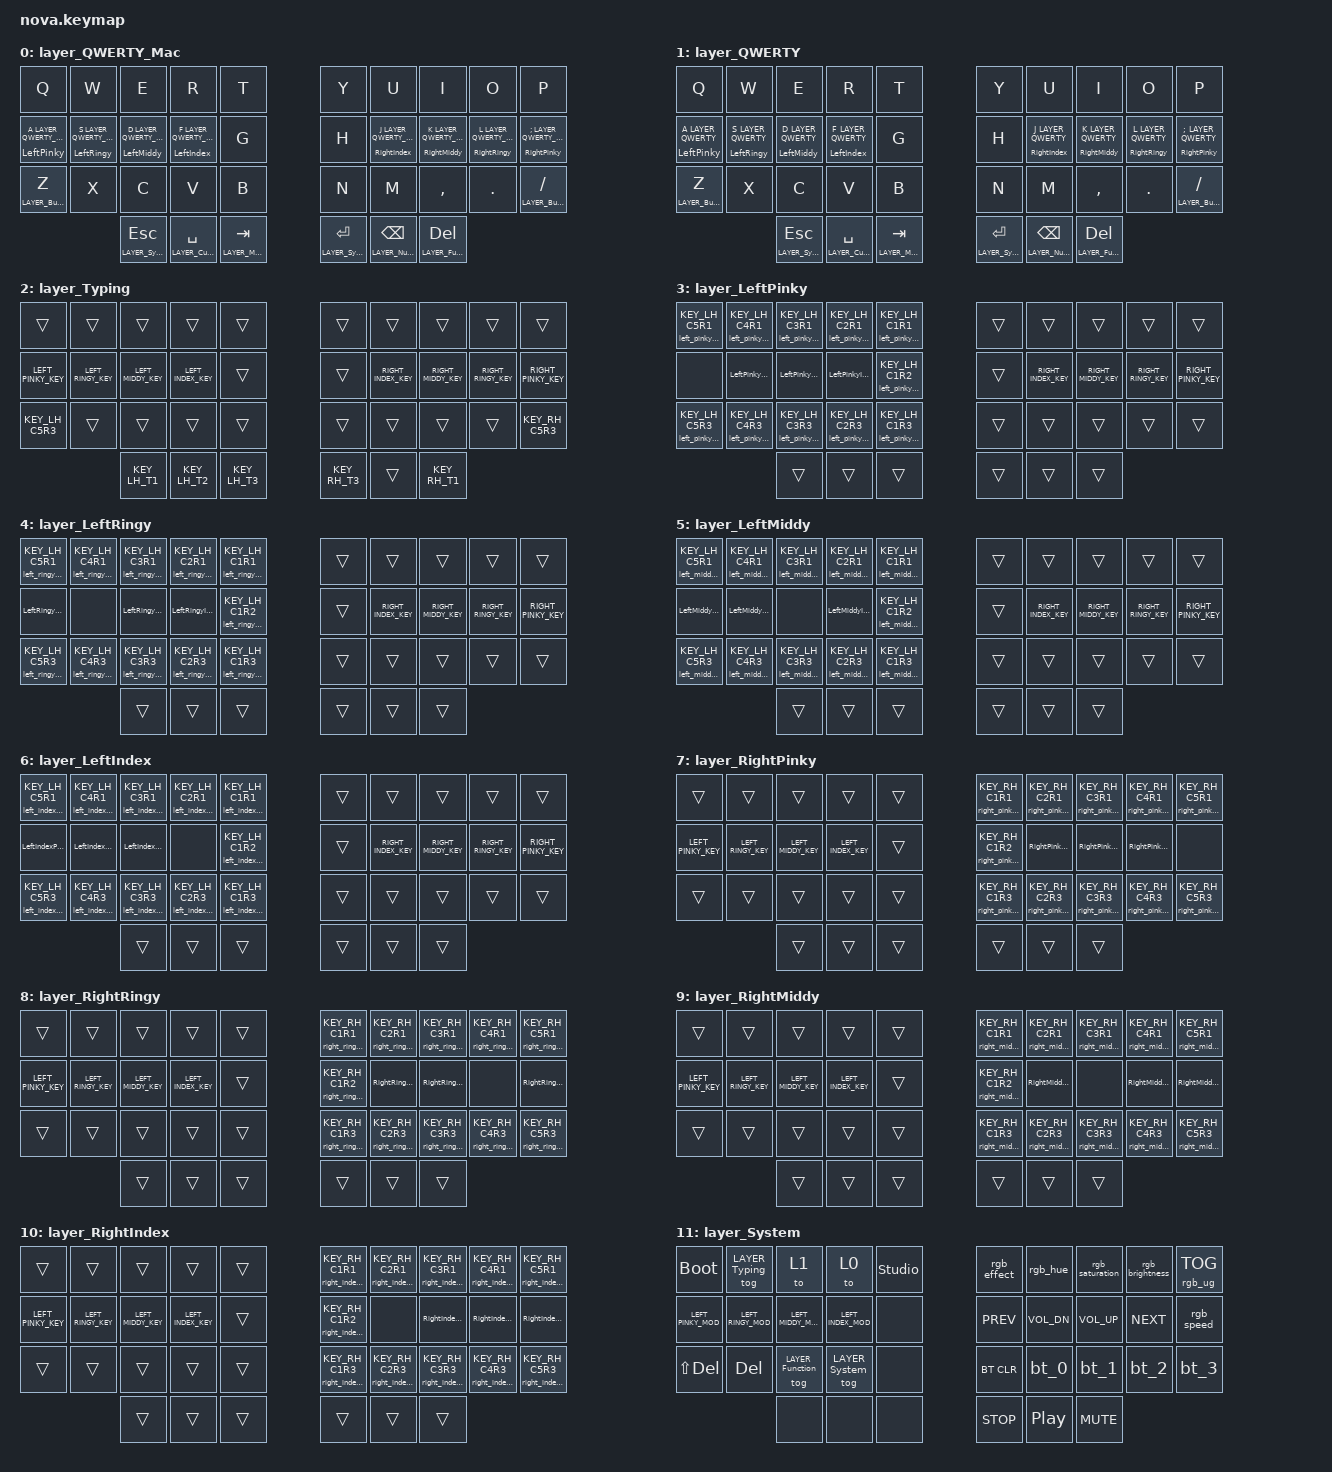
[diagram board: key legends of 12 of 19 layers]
/*
 * Copyright (c) 2020 The ZMK Contributors
 * Copyright (c) 2023 Innaworks Development Limited, trading as MoErgo
 *
 * SPDX-License-Identifier: MIT
 */


/* THIS FILE WAS GENERATED BY GLOVE80 LAYOUT EDITOR
 *
 * This file was generated automatically. You may or may not want to
 * edit it directly.
 */

#include <behaviors.dtsi>
/* Include all behavior includes needed */
#include <dt-bindings/zmk/outputs.h>
#include <dt-bindings/zmk/keys.h>
#include <dt-bindings/zmk/bt.h>
#include <dt-bindings/zmk/rgb.h>

/* On demand includes */


/* Automatically generated layer name #define */
#define LAYER_QWERTY_Mac 0
#define LAYER_QWERTY 1
#define LAYER_Typing 2
#define LAYER_LeftPinky 3
#define LAYER_LeftRingy 4
#define LAYER_LeftMiddy 5
#define LAYER_LeftIndex 6
#define LAYER_RightPinky 7
#define LAYER_RightRingy 8
#define LAYER_RightMiddy 9
#define LAYER_RightIndex 10
#define LAYER_System 11
#define LAYER_Cursor 12
#define LAYER_Mouse 13
#define LAYER_Symbol 14
#define LAYER_Number 15
#define LAYER_Function 16
#define LAYER_Button_Mac 17
#define LAYER_Button 18

#ifndef RGB_STATUS
#define RGB_STATUS 15 0
#endif

/* Custom Device-tree */

/ {
#ifdef BT_DISC_CMD
    behaviors {
        bt_0: bt_0 {
            compatible = "zmk,behavior-tap-dance";
            label = "BT_0";
            #binding-cells = <0>;
            tapping-term-ms = <200>;
            bindings = <&bt_select_0>, <&bt BT_DISC 0>;
        };
        bt_1: bt_1 {
            compatible = "zmk,behavior-tap-dance";
            label = "BT_1";
            #binding-cells = <0>;
            tapping-term-ms = <200>;
            bindings = <&bt_select_1>, <&bt BT_DISC 1>;
        };
        bt_2: bt_2 {
            compatible = "zmk,behavior-tap-dance";
            label = "BT_2";
            #binding-cells = <0>;
            tapping-term-ms = <200>;
            bindings = <&bt_select_2>, <&bt BT_DISC 2>;
        };
        bt_3: bt_3 {
            compatible = "zmk,behavior-tap-dance";
            label = "BT_3";
            #binding-cells = <0>;
            tapping-term-ms = <200>;
            bindings = <&bt_select_3>, <&bt BT_DISC 3>;
        };
    };
    macros {
        bt_select_0: bt_select_0 {
            label = "BT_SELECT_0";
            compatible = "zmk,behavior-macro";
            #binding-cells = <0>;
            bindings
                = <&out OUT_BLE>,
                  <&bt BT_SEL 0>;
        };
        bt_select_1: bt_select_1 {
            label = "BT_SELECT_1";
            compatible = "zmk,behavior-macro";
            #binding-cells = <0>;
            bindings
                = <&out OUT_BLE>,
                  <&bt BT_SEL 1>;
        };
        bt_select_2: bt_select_2 {
            label = "BT_SELECT_2";
            compatible = "zmk,behavior-macro";
            #binding-cells = <0>;
            bindings
                = <&out OUT_BLE>,
                  <&bt BT_SEL 2>;
        };
        bt_select_3: bt_select_3 {
            label = "BT_SELECT_3";
            compatible = "zmk,behavior-macro";
            #binding-cells = <0>;
            bindings
                = <&out OUT_BLE>,
                  <&bt BT_SEL 3>;
        };
    };
#else
    macros {
        bt_0: bt_0 {
            label = "BT_0";
            compatible = "zmk,behavior-macro";
            #binding-cells = <0>;
            bindings
                = <&out OUT_BLE>,
                  <&bt BT_SEL 0>;
        };
        bt_1: bt_1 {
            label = "BT_1";
            compatible = "zmk,behavior-macro";
            #binding-cells = <0>;
            bindings
                = <&out OUT_BLE>,
                  <&bt BT_SEL 1>;
        };
        bt_2: bt_2 {
            label = "BT_2";
            compatible = "zmk,behavior-macro";
            #binding-cells = <0>;
            bindings
                = <&out OUT_BLE>,
                  <&bt BT_SEL 2>;
        };
        bt_3: bt_3 {
            label = "BT_3";
            compatible = "zmk,behavior-macro";
            #binding-cells = <0>;
            bindings
                = <&out OUT_BLE>,
                  <&bt BT_SEL 3>;
        };
    };
#endif
};

/* #define for key positions */
#define POS_LH_T1 30
#define POS_LH_T2 31
#define POS_LH_T3 32
#define POS_LH_C1R1 4
#define POS_LH_C1R2 14
#define POS_LH_C1R3 24
#define POS_LH_C1R4 32
#define POS_LH_C2R1 3
#define POS_LH_C2R2 13
#define POS_LH_C2R3 23
#define POS_LH_C2R4 31
#define POS_LH_C3R1 2
#define POS_LH_C3R2 12
#define POS_LH_C3R3 22
#define POS_LH_C3R4 30
#define POS_LH_C4R1 1
#define POS_LH_C4R2 11
#define POS_LH_C4R3 21
#define POS_LH_C5R1 0
#define POS_LH_C5R2 10
#define POS_LH_C5R3 20
#define POS_RH_T1 35
#define POS_RH_T2 34
#define POS_RH_T3 33
#define POS_RH_C1R1 5
#define POS_RH_C1R2 15
#define POS_RH_C1R3 25
#define POS_RH_C1R4 33
#define POS_RH_C2R1 6
#define POS_RH_C2R2 16
#define POS_RH_C2R3 26
#define POS_RH_C2R4 34
#define POS_RH_C3R1 7
#define POS_RH_C3R2 17
#define POS_RH_C3R3 27
#define POS_RH_C3R4 35
#define POS_RH_C4R1 8
#define POS_RH_C4R2 18
#define POS_RH_C4R3 28
#define POS_RH_C5R1 9
#define POS_RH_C5R2 19
#define POS_RH_C5R3 29

/* Custom Defined Behaviors */
/ {
// NOTE: Use the many #define settings below to customize this keymap!
#define DIFFICULTY_LEVEL  0  // 0:custom, 1:easy -> 5:hard (see below)
#define ENFORCE_BILATERAL    // cancels single-handed home row mod+tap
#define SPACE_FORGIVENESS    // allow lingering taps on the space bar
// TIP: Add more setting overrides here instead of editing them below.

//////////////////////////////////////////////////////////////////////////////
//
// Sunaku's Keymap v41 -- "Glorious Engrammer"
// - https://github.com/sunaku/glove80-keymaps
//
//////////////////////////////////////////////////////////////////////////////

//
// OPERATING_SYSTEM defines which operating system you intend to use
// with this keymap, because shortcuts vary across operating systems.
//
// - https://zmk.dev/docs/codes
// - https://en.wikipedia.org/wiki/Table_of_keyboard_shortcuts
//
// This setting also affects the UNICODE() function defined below, as
// each OS has different shortcuts for typing Unicode hex characters.
//
// NOTE: You may need to enable Unicode hexadecimal input in your OS:
// - (macOS) https://uknowit.uwgb.edu/page.php?id=22623
//     and   https://github.com/ldanet/unicode-hex-input-fix
// - (Linux) https://help.ubuntu.com/stable/ubuntu-help/tips-specialchars.html.en#ctrlshiftu
// - (Windows) https://github.com/samhocevar/wincompose
//
// Specifically, Windows users should be running the WinCompose tool,
// which lets you type Unicode characters via hexadecimal codepoints.
//
// Windows/Linux Def
#define _C      LC
#define _REDO   _C(Y)
#define _UNDO   _C(Z)
#define _CUT    _C(X)
#define _COPY   _C(C)
#define _PASTE  _C(V)
#define _FIND   _C(F)
// Mac Def
#define _C_Mac      LG
#define _REDO_Mac   _C_Mac(LS(Z))
#define _HOME_Mac   _C_Mac(LEFT)
#define _END_Mac    _C_Mac(RIGHT)
#define _UNDO_Mac   _C_Mac(Z)
#define _CUT_Mac    _C_Mac(X)
#define _COPY_Mac   _C_Mac(C)
#define _PASTE_Mac  _C_Mac(V)
#define _FIND_Mac   _C_Mac(F)
#define _PSCRN_Mac  _C_Mac(LS(N4))

//
// Keymap specific knowledge of the base layer's alpha + ZMK layout
//
#define KEY_LH_C5R1 Q
#define KEY_LH_C4R1 W
#define KEY_LH_C3R1 E
#define KEY_LH_C2R1 R
#define KEY_LH_C1R1 T
#define KEY_RH_C1R1 Y
#define KEY_RH_C2R1 U
#define KEY_RH_C3R1 I
#define KEY_RH_C4R1 O
#define KEY_RH_C5R1 P
#define KEY_LH_C5R2 A
#define KEY_LH_C4R2 S
#define KEY_LH_C3R2 D
#define KEY_LH_C2R2 F
#define KEY_LH_C1R2 G
#define KEY_RH_C1R2 H
#define KEY_RH_C2R2 J
#define KEY_RH_C3R2 K
#define KEY_RH_C4R2 L
#define KEY_RH_C5R2 SEMI
#define KEY_LH_C5R3 Z
#define KEY_LH_C4R3 X
#define KEY_LH_C3R3 C
#define KEY_LH_C2R3 V
#define KEY_LH_C1R3 B
#define KEY_RH_C1R3 N
#define KEY_RH_C2R3 M
#define KEY_RH_C3R3 COMMA
#define KEY_RH_C4R3 DOT
#define KEY_RH_C5R3 FSLH
#define KEY_LH_T1 ESC
#define KEY_LH_T2 SPACE
#define KEY_LH_T3 TAB
#define KEY_RH_T3 ENTER
#define KEY_RH_T2 BACKSPACE
#define KEY_RH_T1 DELETE

combos {
  compatible = "zmk,combos";

  //
  // COMBO_FIRING_DECAY defines how much time you have left (milliseconds)
  // after pressing the first key in a ZMK combo to finish the whole chord.
  //
  #ifndef COMBO_FIRING_DECAY
  #define COMBO_FIRING_DECAY 50
  #endif
  combo_caps_lock {
    timeout-ms = <COMBO_FIRING_DECAY>;
    key-positions = <POS_LH_T3 POS_RH_T3>;
    bindings = <&kp CAPSLOCK>;
    layers = <0 1 2 3 4 5 6 7>;
  };
};

behaviors {

  //////////////////////////////////////////////////////////////////////////
  //
  // Miryoku layers and home row mods (ported from my QMK endgame)
  // - https://sunaku.github.io/home-row-mods.html#porting-to-zmk
  // - https://github.com/urob/zmk-config#timeless-homerow-mods
  //
  //////////////////////////////////////////////////////////////////////////

  //
  // DIFFICULTY_LEVEL specifies your level of expertise with this keymap.
  // It's meant to help newcomers gradually work their way up to mastery.
  //
  // #define DIFFICULTY_LEVEL 1 // novice (500ms)
  // #define DIFFICULTY_LEVEL 2 // slower (400ms)
  // #define DIFFICULTY_LEVEL 3 // normal (300ms)
  // #define DIFFICULTY_LEVEL 4 // faster (200ms)
  // #define DIFFICULTY_LEVEL 5 // expert (100ms)
  //
  // You can disable this setting by omitting it or assigning a `0` zero,
  // in which case it will default to my personal set of time thresholds.
  //
  // #define DIFFICULTY_LEVEL 0 // sunaku (150ms)
  //
  // No matter what difficulty level you choose, you can always override
  // any settings in this keymap at the beginning of this configuration.
  //
  #ifdef DIFFICULTY_LEVEL
    #if DIFFICULTY_LEVEL > 0 && DIFFICULTY_LEVEL < 6
      #ifndef TAPPING_RESOLUTION
        #define TAPPING_RESOLUTION ((6 - DIFFICULTY_LEVEL) * 100)
      #endif
    #endif
  #endif

  //
  // TAPPING_RESOLUTION specifies the maximum speed at which the keyboard
  // confuses your taps as being holds when you type on home row mod keys.
  // When you lower this value, the same confusion should still occur; but
  // when you raise this value, you should be able to type normally again.
  //
  #ifndef TAPPING_RESOLUTION
  #define TAPPING_RESOLUTION 150
  #endif

  //
  // ENFORCE_BILATERAL cancels out single-handed home row mods activation by
  // releasing any currently pressed mods and replacing them with plain taps.
  //
  // NOTE: You may still encounter "flashing mods" where an operating system
  // action is triggered by the release of mods, such as LGUI which launches
  // the Windows Start Menu and LALT which opens the Microsoft Office Ribbon.
  //
  //#define ENFORCE_BILATERAL

  //
  // SPACE_FORGIVENESS taps when the symbol layer access key is merely held
  // and released, without any symbol been tapped while the access was held.
  // For example, suppose you hold the symbol layer key and, before pressing
  // another key, you suddenly decide that you don't want the layer anymore:
  //
  // <1> If this setting is enabled, the underlying tap behavior is triggered
  //     to type a single character when you release that layer access key.
  //
  // <2> Otherwise, nothing happens when you release that layer access key.
  //
  // NOTE: This setting interferes with (and effectively disables) per-key
  // RGB indicators (PR30) for layers accessed via thumb layer access keys.
  //
  //#define SPACE_FORGIVENESS

  //
  // The *_FINGER_MOD specify which modifiers are used by home row mod keys.
  // Here, we use Miryoku's "GACS" (Win, Alt, Ctrl, Shift) order by default.
  //
  #ifndef PINKY_FINGER_MOD
  #define PINKY_FINGER_MOD LGUI
  #endif
  #ifndef RINGY_FINGER_MOD
  #define RINGY_FINGER_MOD LALT
  #endif
  #ifndef MIDDY_FINGER_MOD
  #define MIDDY_FINGER_MOD LCTL
  #endif
  #ifndef INDEX_FINGER_MOD
  #define INDEX_FINGER_MOD LSFT
  #endif
  //
  // The following settings let you configure mods individually, per finger:
  //
  #ifndef LEFT_PINKY_MOD
  #define LEFT_PINKY_MOD PINKY_FINGER_MOD
  #endif
  #ifndef RIGHT_PINKY_MOD
  #define RIGHT_PINKY_MOD PINKY_FINGER_MOD
  #endif
  #ifndef LEFT_RINGY_MOD
  #define LEFT_RINGY_MOD RINGY_FINGER_MOD
  #endif
  #ifndef RIGHT_RINGY_MOD
  #define RIGHT_RINGY_MOD RINGY_FINGER_MOD
  #endif
  #ifndef LEFT_MIDDY_MOD
  #define LEFT_MIDDY_MOD MIDDY_FINGER_MOD
  #endif
  #ifndef RIGHT_MIDDY_MOD
  #define RIGHT_MIDDY_MOD MIDDY_FINGER_MOD
  #endif
  #ifndef LEFT_INDEX_MOD
  #define LEFT_INDEX_MOD INDEX_FINGER_MOD
  #endif
  #ifndef RIGHT_INDEX_MOD
  #define RIGHT_INDEX_MOD INDEX_FINGER_MOD
  #endif

  //
  // HOMEY_HOLDING_TYPE defines the flavor of ZMK hold-tap behavior to use
  // for the pinky, ring, and middle fingers (which are assigned to Super,
  // Alt, and Ctrl respectively in the Miryoku system) on home row keys.
  //
  #ifndef HOMEY_HOLDING_TYPE
  #define HOMEY_HOLDING_TYPE "tap-preferred"
  #endif

  //
  // HOMEY_HOLDING_TIME defines how long you need to hold (milliseconds)
  // home row mod keys in order to send their modifiers to the computer
  // (i.e. "register" them) for mod-click mouse usage (e.g. Ctrl-Click).
  //
  #ifndef HOMEY_HOLDING_TIME
  #define HOMEY_HOLDING_TIME (TAPPING_RESOLUTION + 90)
  #endif
  #ifndef INDEX_HOLDING_TIME
  #define INDEX_HOLDING_TIME (TAPPING_RESOLUTION + 20)
  #endif
  #ifndef MIDDY_HOLDING_TIME
  #define MIDDY_HOLDING_TIME (TAPPING_RESOLUTION + 60)
  #endif
  #ifndef RINGY_HOLDING_TIME
  #define RINGY_HOLDING_TIME (TAPPING_RESOLUTION + 90)
  #endif
  #ifndef PINKY_HOLDING_TIME
  #define PINKY_HOLDING_TIME (TAPPING_RESOLUTION + 110)
  #endif

  //
  // HOMEY_STREAK_DECAY defines how long you need to wait (milliseconds)
  // after typing before you can use home row mods again.  It prevents
  // unintended activation of home row mods when you're actively typing.
  //
  #ifndef HOMEY_STREAK_DECAY
  #define HOMEY_STREAK_DECAY TAPPING_RESOLUTION
  #endif

  //
  // HOMEY_REPEAT_DECAY defines how much time you have left (milliseconds)
  // after tapping a key to hold it again in order to make it auto-repeat.
  //
  #ifndef HOMEY_REPEAT_DECAY
  #define HOMEY_REPEAT_DECAY (TAPPING_RESOLUTION + 150)
  #endif // "tap then hold" for key auto-repeat

  //
  // CHORD_HOLDING_TYPE defines the flavor of ZMK hold-tap behavior to use
  // for chorded home row mods (secondary keypresses in multi-mod chords).
  //
  #ifndef CHORD_HOLDING_TYPE
  #define CHORD_HOLDING_TYPE HOMEY_HOLDING_TYPE
  #endif

  //
  // CHORD_HOLDING_TIME defines how long you need to hold (milliseconds)
  // home row mod keys in order to send their modifiers to the computer
  // (i.e. "register" them) for mod-click mouse usage (e.g. Ctrl-Click).
  // This is specifically for secondary keypresses in multi-mod chords.
  //
  #ifndef CHORD_HOLDING_TIME
  #define CHORD_HOLDING_TIME TAPPING_RESOLUTION
  #endif

  //
  // CHORD_STREAK_DECAY defines how long you need to wait (milliseconds)
  // after typing before you can use home row mods again.  It prevents
  // unintended activation of home row mods when you're actively typing
  // This is specifically for secondary keypresses in multi-mod chords.
  //
  #ifndef CHORD_STREAK_DECAY
  #define CHORD_STREAK_DECAY HOMEY_STREAK_DECAY
  #endif

  //
  // CHORD_REPEAT_DECAY defines how much time you have left (milliseconds)
  // after tapping a key to hold it again in order to make it auto-repeat.
  // This is specifically for secondary keypresses in multi-mod chords.
  //
  #ifndef CHORD_REPEAT_DECAY
  #define CHORD_REPEAT_DECAY HOMEY_REPEAT_DECAY
  #endif

  //
  // INDEX_HOLDING_TYPE defines the flavor of ZMK hold-tap behavior to use
  // for index fingers (which Miryoku assigns to Shift) on home row keys.
  //
  // NOTE: The "tap-preferred" flavor of ZMK hold-tap for index finger keys
  // allows faster activation of the Shift modifier (without having to wait
  // for the modified key to be released as the "balanced" flavor requires).
  //
  #ifndef INDEX_HOLDING_TYPE
  #define INDEX_HOLDING_TYPE "tap-preferred"
  #endif

  //
  // INDEX_STREAK_DECAY defines how long you need to wait (milliseconds)
  // after typing before you can use home row mods again.  It prevents
  // unintended activation of home row mods when you're actively typing.
  //
  #ifndef INDEX_STREAK_DECAY
  #define INDEX_STREAK_DECAY (TAPPING_RESOLUTION - 50)
  #endif

  //
  // INDEX_REPEAT_DECAY defines how much time you have left (milliseconds)
  // after tapping a key to hold it again in order to make it auto-repeat.
  //
  #ifndef INDEX_REPEAT_DECAY
  #define INDEX_REPEAT_DECAY (TAPPING_RESOLUTION + 150)
  #endif // "tap then hold" for key auto-repeat

  //
  // PLAIN_HOLDING_TYPE defines the flavor of ZMK hold-tap behavior to use
  // for index fingers (which Miryoku assigns to Shift) on home row keys.
  //
  // NOTE: The "tap-preferred" flavor of ZMK hold-tap for index finger keys
  // allows faster activation of the Shift modifier (without having to wait
  // for the modified key to be released as the "balanced" flavor requires).
  //
  #ifndef PLAIN_HOLDING_TYPE
  #define PLAIN_HOLDING_TYPE INDEX_HOLDING_TYPE
  #endif

  //
  // PLAIN_HOLDING_TIME defines how long you need to hold (milliseconds)
  // index finger keys in order to send their modifiers to the computer
  // (i.e. "register" them) for mod-click mouse usage (e.g. Shift-Click).
  //
  #ifndef PLAIN_HOLDING_TIME
  #define PLAIN_HOLDING_TIME (TAPPING_RESOLUTION + 50)
  #endif

  //
  // PLAIN_STREAK_DECAY defines how long you need to wait (milliseconds)
  // after typing before you can use home row mods again.  It prevents
  // unintended activation of home row mods when you're actively typing.
  //
  #ifndef PLAIN_STREAK_DECAY
  #define PLAIN_STREAK_DECAY HOMEY_STREAK_DECAY
  #endif

  //
  // PLAIN_REPEAT_DECAY defines how much time you have left (milliseconds)
  // after tapping a key to hold it again in order to make it auto-repeat.
  //
  #ifndef PLAIN_REPEAT_DECAY
  #define PLAIN_REPEAT_DECAY (TAPPING_RESOLUTION + 150)
  #endif // "tap then hold" for key auto-repeat

  //
  // THUMB_HOLDING_TYPE defines the flavor of ZMK hold-tap behavior to use
  // for the thumbs (which are assigned to 6 layers in the Miryoku system).
  //
  // NOTE: The "balanced" flavor of ZMK hold-tap provides instant modifier
  // activation for the symbol layer (if the tapped symbol key is released
  // while the thumb layer key is still held down) for quicker programming.
  //
  #ifndef THUMB_HOLDING_TYPE
  #define THUMB_HOLDING_TYPE "balanced"
  #endif

  //
  // THUMB_HOLDING_TIME defines how long you need to hold (milliseconds)
  // a thumb key to activate a layer.  Shorter holds are treated as taps.
  //
  #ifndef THUMB_HOLDING_TIME
  #define THUMB_HOLDING_TIME (TAPPING_RESOLUTION + 50)
  #endif

  //
  // THUMB_REPEAT_DECAY defines how much time you have left (milliseconds)
  // after tapping a key to hold it again in order to make it auto-repeat.
  //
  #ifndef THUMB_REPEAT_DECAY
  #define THUMB_REPEAT_DECAY (TAPPING_RESOLUTION + 150)
  #endif // "tap then hold" for key auto-repeat

  //
  // SPACE_HOLDING_TYPE defines the flavor of ZMK hold-tap behavior to use
  // for spacebar (assigned to the right thumb's home position by default).
  //
  #ifndef SPACE_HOLDING_TYPE
  #define SPACE_HOLDING_TYPE THUMB_HOLDING_TYPE
  #endif

  //
  // SPACE_HOLDING_TIME defines how long you need to hold (milliseconds)
  // the space thumb key to activate.  Shorter holds are treated as taps.
  //
  #ifndef SPACE_HOLDING_TIME
  #define SPACE_HOLDING_TIME (TAPPING_RESOLUTION + 20)
  #endif

  //
  // SPACE_REPEAT_DECAY defines how much time you have left (milliseconds)
  // after tapping a key to hold it again in order to make it auto-repeat.
  //
  #ifndef SPACE_REPEAT_DECAY
  #define SPACE_REPEAT_DECAY TAPPING_RESOLUTION
  #endif

  //
  // Nova key positions index for positional hold-tap
  //
  // |--------------------|--------------------|
  // | LEFT_HAND_KEYS     |    RIGHT_HAND_KEYS |
  // |                    |                    |
  // |  0  1  2  3  4     |      5  6  7  8  9 |
  // | 10 11 12 13 14     |     15 16 17 18 19 |
  // | 20 21 22 23 24     |     25 26 27 28 29 |
  // |       30 31 32     |     33 34 35       |
  // |--------------------|--------------------|
  //
  #define LEFT_HAND_KEYS  \
          0  1  2  3  4   \
         10 11 12 13 14   \
         20 21 22 23 24
  #define RIGHT_HAND_KEYS \
                                 5  6  7  8  9 \
                                15 16 17 18 19 \
                                25 26 27 28 29
  #define THUMB_KEYS      \
               30 31 32         33 34 35

  #define LEFT_PINKY_KEY  KEY_LH_C5R2
  #define LEFT_RINGY_KEY  KEY_LH_C4R2
  #define LEFT_MIDDY_KEY  KEY_LH_C3R2
  #define LEFT_INDEX_KEY  KEY_LH_C2R2

  #define RIGHT_PINKY_KEY KEY_RH_C5R2
  #define RIGHT_RINGY_KEY KEY_RH_C4R2
  #define RIGHT_MIDDY_KEY KEY_RH_C3R2
  #define RIGHT_INDEX_KEY KEY_RH_C2R2

  //
  // Home row mods with bilateral combinations support
  //
  #ifndef PINKY_HOLDING_TYPE
  #define PINKY_HOLDING_TYPE HOMEY_HOLDING_TYPE
  #endif
  #ifndef PINKY_CHORD_HOLDING_TYPE
  #define PINKY_CHORD_HOLDING_TYPE CHORD_HOLDING_TYPE
  #endif
  #ifndef LEFT_PINKY_CHORD_HOLDING_TYPE
  #define LEFT_PINKY_CHORD_HOLDING_TYPE PINKY_CHORD_HOLDING_TYPE
  #endif
  #ifndef RIGHT_PINKY_CHORD_HOLDING_TYPE
  #define RIGHT_PINKY_CHORD_HOLDING_TYPE PINKY_CHORD_HOLDING_TYPE
  #endif
  #ifndef PINKY_HOLDING_TIME
  #define PINKY_HOLDING_TIME HOMEY_HOLDING_TIME
  #endif
  #ifndef PINKY_CHORD_HOLDING_TIME
  #define PINKY_CHORD_HOLDING_TIME CHORD_HOLDING_TIME
  #endif
  #ifndef LEFT_PINKY_CHORD_HOLDING_TIME
  #define LEFT_PINKY_CHORD_HOLDING_TIME PINKY_CHORD_HOLDING_TIME
  #endif
  #ifndef RIGHT_PINKY_CHORD_HOLDING_TIME
  #define RIGHT_PINKY_CHORD_HOLDING_TIME PINKY_CHORD_HOLDING_TIME
  #endif
  #ifndef PINKY_STREAK_DECAY
  #define PINKY_STREAK_DECAY HOMEY_STREAK_DECAY
  #endif
  #ifndef PINKY_CHORD_STREAK_DECAY
  #define PINKY_CHORD_STREAK_DECAY CHORD_STREAK_DECAY
  #endif
  #ifndef LEFT_PINKY_CHORD_STREAK_DECAY
  #define LEFT_PINKY_CHORD_STREAK_DECAY PINKY_CHORD_STREAK_DECAY
  #endif
  #ifndef RIGHT_PINKY_CHORD_STREAK_DECAY
  #define RIGHT_PINKY_CHORD_STREAK_DECAY PINKY_CHORD_STREAK_DECAY
  #endif
  #ifndef PINKY_REPEAT_DECAY
  #define PINKY_REPEAT_DECAY HOMEY_REPEAT_DECAY
  #endif
  #ifndef PINKY_CHORD_REPEAT_DECAY
  #define PINKY_CHORD_REPEAT_DECAY CHORD_REPEAT_DECAY
  #endif
  #ifndef LEFT_PINKY_CHORD_REPEAT_DECAY
  #define LEFT_PINKY_CHORD_REPEAT_DECAY PINKY_CHORD_REPEAT_DECAY
  #endif
  #ifndef RIGHT_PINKY_CHORD_REPEAT_DECAY
  #define RIGHT_PINKY_CHORD_REPEAT_DECAY PINKY_CHORD_REPEAT_DECAY
  #endif
  #ifndef RINGY_HOLDING_TYPE
  #define RINGY_HOLDING_TYPE HOMEY_HOLDING_TYPE
  #endif
  #ifndef RINGY_CHORD_HOLDING_TYPE
  #define RINGY_CHORD_HOLDING_TYPE CHORD_HOLDING_TYPE
  #endif
  #ifndef LEFT_RINGY_CHORD_HOLDING_TYPE
  #define LEFT_RINGY_CHORD_HOLDING_TYPE RINGY_CHORD_HOLDING_TYPE
  #endif
  #ifndef RIGHT_RINGY_CHORD_HOLDING_TYPE
  #define RIGHT_RINGY_CHORD_HOLDING_TYPE RINGY_CHORD_HOLDING_TYPE
  #endif
  #ifndef RINGY_HOLDING_TIME
  #define RINGY_HOLDING_TIME HOMEY_HOLDING_TIME
  #endif
  #ifndef RINGY_CHORD_HOLDING_TIME
  #define RINGY_CHORD_HOLDING_TIME CHORD_HOLDING_TIME
  #endif
  #ifndef LEFT_RINGY_CHORD_HOLDING_TIME
  #define LEFT_RINGY_CHORD_HOLDING_TIME RINGY_CHORD_HOLDING_TIME
  #endif
  #ifndef RIGHT_RINGY_CHORD_HOLDING_TIME
  #define RIGHT_RINGY_CHORD_HOLDING_TIME RINGY_CHORD_HOLDING_TIME
  #endif
  #ifndef RINGY_STREAK_DECAY
  #define RINGY_STREAK_DECAY HOMEY_STREAK_DECAY
  #endif
  #ifndef RINGY_CHORD_STREAK_DECAY
  #define RINGY_CHORD_STREAK_DECAY CHORD_STREAK_DECAY
  #endif
  #ifndef LEFT_RINGY_CHORD_STREAK_DECAY
  #define LEFT_RINGY_CHORD_STREAK_DECAY RINGY_CHORD_STREAK_DECAY
  #endif
  #ifndef RIGHT_RINGY_CHORD_STREAK_DECAY
  #define RIGHT_RINGY_CHORD_STREAK_DECAY RINGY_CHORD_STREAK_DECAY
  #endif
  #ifndef RINGY_REPEAT_DECAY
  #define RINGY_REPEAT_DECAY HOMEY_REPEAT_DECAY
  #endif
  #ifndef RINGY_CHORD_REPEAT_DECAY
  #define RINGY_CHORD_REPEAT_DECAY CHORD_REPEAT_DECAY
  #endif
  #ifndef LEFT_RINGY_CHORD_REPEAT_DECAY
  #define LEFT_RINGY_CHORD_REPEAT_DECAY RINGY_CHORD_REPEAT_DECAY
  #endif
  #ifndef RIGHT_RINGY_CHORD_REPEAT_DECAY
  #define RIGHT_RINGY_CHORD_REPEAT_DECAY RINGY_CHORD_REPEAT_DECAY
  #endif
  #ifndef MIDDY_HOLDING_TYPE
  #define MIDDY_HOLDING_TYPE HOMEY_HOLDING_TYPE
  #endif
  #ifndef MIDDY_CHORD_HOLDING_TYPE
  #define MIDDY_CHORD_HOLDING_TYPE CHORD_HOLDING_TYPE
  #endif
  #ifndef LEFT_MIDDY_CHORD_HOLDING_TYPE
  #define LEFT_MIDDY_CHORD_HOLDING_TYPE MIDDY_CHORD_HOLDING_TYPE
  #endif
  #ifndef RIGHT_MIDDY_CHORD_HOLDING_TYPE
  #define RIGHT_MIDDY_CHORD_HOLDING_TYPE MIDDY_CHORD_HOLDING_TYPE
  #endif
  #ifndef MIDDY_HOLDING_TIME
  #define MIDDY_HOLDING_TIME HOMEY_HOLDING_TIME
  #endif
  #ifndef MIDDY_CHORD_HOLDING_TIME
  #define MIDDY_CHORD_HOLDING_TIME CHORD_HOLDING_TIME
  #endif
  #ifndef LEFT_MIDDY_CHORD_HOLDING_TIME
  #define LEFT_MIDDY_CHORD_HOLDING_TIME MIDDY_CHORD_HOLDING_TIME
  #endif
  #ifndef RIGHT_MIDDY_CHORD_HOLDING_TIME
  #define RIGHT_MIDDY_CHORD_HOLDING_TIME MIDDY_CHORD_HOLDING_TIME
  #endif
  #ifndef MIDDY_STREAK_DECAY
  #define MIDDY_STREAK_DECAY HOMEY_STREAK_DECAY
  #endif
  #ifndef MIDDY_CHORD_STREAK_DECAY
  #define MIDDY_CHORD_STREAK_DECAY CHORD_STREAK_DECAY
  #endif
  #ifndef LEFT_MIDDY_CHORD_STREAK_DECAY
  #define LEFT_MIDDY_CHORD_STREAK_DECAY MIDDY_CHORD_STREAK_DECAY
  #endif
  #ifndef RIGHT_MIDDY_CHORD_STREAK_DECAY
  #define RIGHT_MIDDY_CHORD_STREAK_DECAY MIDDY_CHORD_STREAK_DECAY
  #endif
  #ifndef MIDDY_REPEAT_DECAY
  #define MIDDY_REPEAT_DECAY HOMEY_REPEAT_DECAY
  #endif
  #ifndef MIDDY_CHORD_REPEAT_DECAY
  #define MIDDY_CHORD_REPEAT_DECAY CHORD_REPEAT_DECAY
  #endif
  #ifndef LEFT_MIDDY_CHORD_REPEAT_DECAY
  #define LEFT_MIDDY_CHORD_REPEAT_DECAY MIDDY_CHORD_REPEAT_DECAY
  #endif
  #ifndef RIGHT_MIDDY_CHORD_REPEAT_DECAY
  #define RIGHT_MIDDY_CHORD_REPEAT_DECAY MIDDY_CHORD_REPEAT_DECAY
  #endif
  #ifndef INDEX_HOLDING_TYPE
  #define INDEX_HOLDING_TYPE HOMEY_HOLDING_TYPE
  #endif
  #ifndef INDEX_CHORD_HOLDING_TYPE
  #define INDEX_CHORD_HOLDING_TYPE CHORD_HOLDING_TYPE
  #endif
  #ifndef LEFT_INDEX_CHORD_HOLDING_TYPE
  #define LEFT_INDEX_CHORD_HOLDING_TYPE INDEX_CHORD_HOLDING_TYPE
  #endif
  #ifndef RIGHT_INDEX_CHORD_HOLDING_TYPE
  #define RIGHT_INDEX_CHORD_HOLDING_TYPE INDEX_CHORD_HOLDING_TYPE
  #endif
  #ifndef INDEX_HOLDING_TIME
  #define INDEX_HOLDING_TIME HOMEY_HOLDING_TIME
  #endif
  #ifndef INDEX_CHORD_HOLDING_TIME
  #define INDEX_CHORD_HOLDING_TIME CHORD_HOLDING_TIME
  #endif
  #ifndef LEFT_INDEX_CHORD_HOLDING_TIME
  #define LEFT_INDEX_CHORD_HOLDING_TIME INDEX_CHORD_HOLDING_TIME
  #endif
  #ifndef RIGHT_INDEX_CHORD_HOLDING_TIME
  #define RIGHT_INDEX_CHORD_HOLDING_TIME INDEX_CHORD_HOLDING_TIME
  #endif
  #ifndef INDEX_STREAK_DECAY
  #define INDEX_STREAK_DECAY HOMEY_STREAK_DECAY
  #endif
  #ifndef INDEX_CHORD_STREAK_DECAY
  #define INDEX_CHORD_STREAK_DECAY CHORD_STREAK_DECAY
  #endif
  #ifndef LEFT_INDEX_CHORD_STREAK_DECAY
  #define LEFT_INDEX_CHORD_STREAK_DECAY INDEX_CHORD_STREAK_DECAY
  #endif
  #ifndef RIGHT_INDEX_CHORD_STREAK_DECAY
  #define RIGHT_INDEX_CHORD_STREAK_DECAY INDEX_CHORD_STREAK_DECAY
  #endif
  #ifndef INDEX_REPEAT_DECAY
  #define INDEX_REPEAT_DECAY HOMEY_REPEAT_DECAY
  #endif
  #ifndef INDEX_CHORD_REPEAT_DECAY
  #define INDEX_CHORD_REPEAT_DECAY CHORD_REPEAT_DECAY
  #endif
  #ifndef LEFT_INDEX_CHORD_REPEAT_DECAY
  #define LEFT_INDEX_CHORD_REPEAT_DECAY INDEX_CHORD_REPEAT_DECAY
  #endif
  #ifndef RIGHT_INDEX_CHORD_REPEAT_DECAY
  #define RIGHT_INDEX_CHORD_REPEAT_DECAY INDEX_CHORD_REPEAT_DECAY
  #endif
  #ifndef LEFT_PINKY_HOLDING_TYPE
  #define LEFT_PINKY_HOLDING_TYPE PINKY_HOLDING_TYPE
  #endif
  #ifndef LEFT_PINKY_HOLDING_TIME
  #define LEFT_PINKY_HOLDING_TIME PINKY_HOLDING_TIME
  #endif
  #ifndef LEFT_PINKY_STREAK_DECAY
  #define LEFT_PINKY_STREAK_DECAY PINKY_STREAK_DECAY
  #endif
  #ifndef LEFT_PINKY_REPEAT_DECAY
  #define LEFT_PINKY_REPEAT_DECAY PINKY_REPEAT_DECAY
  #endif
  left_pinky: homey_left_pinky {
    compatible = "zmk,behavior-hold-tap";
    flavor = LEFT_PINKY_HOLDING_TYPE;
    hold-trigger-key-positions = <RIGHT_HAND_KEYS THUMB_KEYS>;
    hold-trigger-on-release; // wait for other home row mods
    tapping-term-ms = <LEFT_PINKY_HOLDING_TIME>;
    quick-tap-ms = <LEFT_PINKY_REPEAT_DECAY>;
    require-prior-idle-ms = <LEFT_PINKY_STREAK_DECAY>;
    #binding-cells = <2>;
    bindings = <&kp>, <&kp>;
  };
  left_pinky_bilateral: homey_left_pinky_bilateral {
    compatible = "zmk,behavior-hold-tap";
    flavor = LEFT_PINKY_HOLDING_TYPE;
    hold-trigger-key-positions = <RIGHT_HAND_KEYS THUMB_KEYS>;
    hold-trigger-on-release; // wait for other home row mods
    tapping-term-ms = <LEFT_PINKY_HOLDING_TIME>;
    quick-tap-ms = <LEFT_PINKY_REPEAT_DECAY>;
    require-prior-idle-ms = <LEFT_PINKY_STREAK_DECAY>;
    #binding-cells = <2>;
    bindings = <&left_pinky_hold>, <&kp>;
  };
  left_pinky_hold: homey_left_pinky_hold {
    compatible = "zmk,behavior-macro-one-param";
    wait-ms = <0>;
    tap-ms = <0>;
    #binding-cells = <1>;
    bindings
      = <&macro_param_1to1>
      , <&macro_press &kp MACRO_PLACEHOLDER>
      #ifdef LAYER_LeftPinky
      , <&macro_press &mo LAYER_LeftPinky>
      #endif
      , <&macro_pause_for_release>
      , <&macro_param_1to1>
      , <&macro_release &kp MACRO_PLACEHOLDER>
      #ifdef LAYER_LeftPinky
      , <&macro_release &mo LAYER_LeftPinky>
      #endif
      ;
  };
  left_pinky_tap: homey_left_pinky_tap {
    compatible = "zmk,behavior-macro-one-param";
    wait-ms = <0>;
    tap-ms = <0>;
    #binding-cells = <1>;
    bindings
      = <&macro_release
          &kp LSFT &kp RSFT
          &kp LALT &kp RALT
          &kp LCTL &kp RCTL
          &kp LGUI &kp RGUI>
      , <&macro_tap &kp LEFT_PINKY_KEY>
      , <&macro_param_1to1>
      , <&macro_tap &kp MACRO_PLACEHOLDER>
      ;
  };
  #define LeftPinky(key, layer_index) LeftPinky_unroll(layer_index) (key)
  #define LeftPinky_unroll(layer_index) LeftPinky_concat(LeftPinky_layer, layer_index)
  #define LeftPinky_concat(prefix, layer_index) prefix ## layer_index
  #ifdef ENFORCE_BILATERAL
  #define left_pinky_layer0_variant left_pinky_bilateral
  #else
  #define left_pinky_layer0_variant left_pinky
  #endif
  #define LeftPinky_layer0(key) left_pinky_layer0_variant LEFT_PINKY_MOD key
  #define LeftPinky_layer1(key) left_pinky LEFT_PINKY_MOD key
  #define LeftPinky_layer2(key) left_pinky LEFT_PINKY_MOD key
  #define LeftPinky_layer3(key) left_pinky LEFT_PINKY_MOD key
  #define LeftPinky_layer4(key) left_pinky LEFT_PINKY_MOD key
  #define LeftPinky_layer5(key) left_pinky LEFT_PINKY_MOD key
  #define LeftPinky_layer6(key) left_pinky LEFT_PINKY_MOD key
  #define LeftPinky_layer7(key) left_pinky LEFT_PINKY_MOD key
  #ifndef RIGHT_PINKY_HOLDING_TYPE
  #define RIGHT_PINKY_HOLDING_TYPE PINKY_HOLDING_TYPE
  #endif
  #ifndef RIGHT_PINKY_HOLDING_TIME
  #define RIGHT_PINKY_HOLDING_TIME PINKY_HOLDING_TIME
  #endif
  #ifndef RIGHT_PINKY_STREAK_DECAY
  #define RIGHT_PINKY_STREAK_DECAY PINKY_STREAK_DECAY
  #endif
  #ifndef RIGHT_PINKY_REPEAT_DECAY
  #define RIGHT_PINKY_REPEAT_DECAY PINKY_REPEAT_DECAY
  #endif
  right_pinky: homey_right_pinky {
    compatible = "zmk,behavior-hold-tap";
    flavor = RIGHT_PINKY_HOLDING_TYPE;
    hold-trigger-key-positions = <LEFT_HAND_KEYS THUMB_KEYS>;
    hold-trigger-on-release; // wait for other home row mods
    tapping-term-ms = <RIGHT_PINKY_HOLDING_TIME>;
    quick-tap-ms = <RIGHT_PINKY_REPEAT_DECAY>;
    require-prior-idle-ms = <RIGHT_PINKY_STREAK_DECAY>;
    #binding-cells = <2>;
    bindings = <&kp>, <&kp>;
  };
  right_pinky_bilateral: homey_right_pinky_bilateral {
    compatible = "zmk,behavior-hold-tap";
    flavor = RIGHT_PINKY_HOLDING_TYPE;
    hold-trigger-key-positions = <LEFT_HAND_KEYS THUMB_KEYS>;
    hold-trigger-on-release; // wait for other home row mods
    tapping-term-ms = <RIGHT_PINKY_HOLDING_TIME>;
    quick-tap-ms = <RIGHT_PINKY_REPEAT_DECAY>;
    require-prior-idle-ms = <RIGHT_PINKY_STREAK_DECAY>;
    #binding-cells = <2>;
    bindings = <&right_pinky_hold>, <&kp>;
  };
  right_pinky_hold: homey_right_pinky_hold {
    compatible = "zmk,behavior-macro-one-param";
    wait-ms = <0>;
    tap-ms = <0>;
    #binding-cells = <1>;
    bindings
      = <&macro_param_1to1>
      , <&macro_press &kp MACRO_PLACEHOLDER>
      #ifdef LAYER_RightPinky
      , <&macro_press &mo LAYER_RightPinky>
      #endif
      , <&macro_pause_for_release>
      , <&macro_param_1to1>
      , <&macro_release &kp MACRO_PLACEHOLDER>
      #ifdef LAYER_RightPinky
      , <&macro_release &mo LAYER_RightPinky>
      #endif
      ;
  };
  right_pinky_tap: homey_right_pinky_tap {
    compatible = "zmk,behavior-macro-one-param";
    wait-ms = <0>;
    tap-ms = <0>;
    #binding-cells = <1>;
    bindings
      = <&macro_release
          &kp LSFT &kp RSFT
          &kp LALT &kp RALT
          &kp LCTL &kp RCTL
          &kp LGUI &kp RGUI>
      , <&macro_tap &kp RIGHT_PINKY_KEY>
      , <&macro_param_1to1>
      , <&macro_tap &kp MACRO_PLACEHOLDER>
      ;
  };
  #define RightPinky(key, layer_index) RightPinky_unroll(layer_index) (key)
  #define RightPinky_unroll(layer_index) RightPinky_concat(RightPinky_layer, layer_index)
  #define RightPinky_concat(prefix, layer_index) prefix ## layer_index
  #ifdef ENFORCE_BILATERAL
  #define right_pinky_layer0_variant right_pinky_bilateral
  #else
  #define right_pinky_layer0_variant right_pinky
  #endif
  #define RightPinky_layer0(key) right_pinky_layer0_variant RIGHT_PINKY_MOD key
  #define RightPinky_layer1(key) right_pinky RIGHT_PINKY_MOD key
  #define RightPinky_layer2(key) right_pinky RIGHT_PINKY_MOD key
  #define RightPinky_layer3(key) right_pinky RIGHT_PINKY_MOD key
  #define RightPinky_layer4(key) right_pinky RIGHT_PINKY_MOD key
  #define RightPinky_layer5(key) right_pinky RIGHT_PINKY_MOD key
  #define RightPinky_layer6(key) right_pinky RIGHT_PINKY_MOD key
  #define RightPinky_layer7(key) right_pinky RIGHT_PINKY_MOD key
  #ifndef LEFT_RINGY_HOLDING_TYPE
  #define LEFT_RINGY_HOLDING_TYPE RINGY_HOLDING_TYPE
  #endif
  #ifndef LEFT_RINGY_HOLDING_TIME
  #define LEFT_RINGY_HOLDING_TIME RINGY_HOLDING_TIME
  #endif
  #ifndef LEFT_RINGY_STREAK_DECAY
  #define LEFT_RINGY_STREAK_DECAY RINGY_STREAK_DECAY
  #endif
  #ifndef LEFT_RINGY_REPEAT_DECAY
  #define LEFT_RINGY_REPEAT_DECAY RINGY_REPEAT_DECAY
  #endif
  left_ringy: homey_left_ringy {
    compatible = "zmk,behavior-hold-tap";
    flavor = LEFT_RINGY_HOLDING_TYPE;
    hold-trigger-key-positions = <RIGHT_HAND_KEYS THUMB_KEYS>;
    hold-trigger-on-release; // wait for other home row mods
    tapping-term-ms = <LEFT_RINGY_HOLDING_TIME>;
    quick-tap-ms = <LEFT_RINGY_REPEAT_DECAY>;
    require-prior-idle-ms = <LEFT_RINGY_STREAK_DECAY>;
    #binding-cells = <2>;
    bindings = <&kp>, <&kp>;
  };
  left_ringy_bilateral: homey_left_ringy_bilateral {
    compatible = "zmk,behavior-hold-tap";
    flavor = LEFT_RINGY_HOLDING_TYPE;
    hold-trigger-key-positions = <RIGHT_HAND_KEYS THUMB_KEYS>;
    hold-trigger-on-release; // wait for other home row mods
    tapping-term-ms = <LEFT_RINGY_HOLDING_TIME>;
    quick-tap-ms = <LEFT_RINGY_REPEAT_DECAY>;
    require-prior-idle-ms = <LEFT_RINGY_STREAK_DECAY>;
    #binding-cells = <2>;
    bindings = <&left_ringy_hold>, <&kp>;
  };
  left_ringy_hold: homey_left_ringy_hold {
    compatible = "zmk,behavior-macro-one-param";
    wait-ms = <0>;
    tap-ms = <0>;
    #binding-cells = <1>;
    bindings
      = <&macro_param_1to1>
      , <&macro_press &kp MACRO_PLACEHOLDER>
      #ifdef LAYER_LeftRingy
      , <&macro_press &mo LAYER_LeftRingy>
      #endif
      , <&macro_pause_for_release>
      , <&macro_param_1to1>
      , <&macro_release &kp MACRO_PLACEHOLDER>
      #ifdef LAYER_LeftRingy
      , <&macro_release &mo LAYER_LeftRingy>
      #endif
      ;
  };
  left_ringy_tap: homey_left_ringy_tap {
    compatible = "zmk,behavior-macro-one-param";
    wait-ms = <0>;
    tap-ms = <0>;
    #binding-cells = <1>;
    bindings
      = <&macro_release
          &kp LSFT &kp RSFT
          &kp LALT &kp RALT
          &kp LCTL &kp RCTL
          &kp LGUI &kp RGUI>
      , <&macro_tap &kp LEFT_RINGY_KEY>
      , <&macro_param_1to1>
      , <&macro_tap &kp MACRO_PLACEHOLDER>
      ;
  };
  #define LeftRingy(key, layer_index) LeftRingy_unroll(layer_index) (key)
  #define LeftRingy_unroll(layer_index) LeftRingy_concat(LeftRingy_layer, layer_index)
  #define LeftRingy_concat(prefix, layer_index) prefix ## layer_index
  #ifdef ENFORCE_BILATERAL
  #define left_ringy_layer0_variant left_ringy_bilateral
  #else
  #define left_ringy_layer0_variant left_ringy
  #endif
  #define LeftRingy_layer0(key) left_ringy_layer0_variant LEFT_RINGY_MOD key
  #define LeftRingy_layer1(key) left_ringy LEFT_RINGY_MOD key
  #define LeftRingy_layer2(key) left_ringy LEFT_RINGY_MOD key
  #define LeftRingy_layer3(key) left_ringy LEFT_RINGY_MOD key
  #define LeftRingy_layer4(key) left_ringy LEFT_RINGY_MOD key
  #define LeftRingy_layer5(key) left_ringy LEFT_RINGY_MOD key
  #define LeftRingy_layer6(key) left_ringy LEFT_RINGY_MOD key
  #define LeftRingy_layer7(key) left_ringy LEFT_RINGY_MOD key
  #ifndef RIGHT_RINGY_HOLDING_TYPE
  #define RIGHT_RINGY_HOLDING_TYPE RINGY_HOLDING_TYPE
  #endif
  #ifndef RIGHT_RINGY_HOLDING_TIME
  #define RIGHT_RINGY_HOLDING_TIME RINGY_HOLDING_TIME
  #endif
  #ifndef RIGHT_RINGY_STREAK_DECAY
  #define RIGHT_RINGY_STREAK_DECAY RINGY_STREAK_DECAY
  #endif
  #ifndef RIGHT_RINGY_REPEAT_DECAY
  #define RIGHT_RINGY_REPEAT_DECAY RINGY_REPEAT_DECAY
  #endif
  right_ringy: homey_right_ringy {
    compatible = "zmk,behavior-hold-tap";
    flavor = RIGHT_RINGY_HOLDING_TYPE;
    hold-trigger-key-positions = <LEFT_HAND_KEYS THUMB_KEYS>;
    hold-trigger-on-release; // wait for other home row mods
    tapping-term-ms = <RIGHT_RINGY_HOLDING_TIME>;
    quick-tap-ms = <RIGHT_RINGY_REPEAT_DECAY>;
    require-prior-idle-ms = <RIGHT_RINGY_STREAK_DECAY>;
    #binding-cells = <2>;
    bindings = <&kp>, <&kp>;
  };
  right_ringy_bilateral: homey_right_ringy_bilateral {
    compatible = "zmk,behavior-hold-tap";
    flavor = RIGHT_RINGY_HOLDING_TYPE;
    hold-trigger-key-positions = <LEFT_HAND_KEYS THUMB_KEYS>;
    hold-trigger-on-release; // wait for other home row mods
    tapping-term-ms = <RIGHT_RINGY_HOLDING_TIME>;
    quick-tap-ms = <RIGHT_RINGY_REPEAT_DECAY>;
    require-prior-idle-ms = <RIGHT_RINGY_STREAK_DECAY>;
    #binding-cells = <2>;
    bindings = <&right_ringy_hold>, <&kp>;
  };
  right_ringy_hold: homey_right_ringy_hold {
    compatible = "zmk,behavior-macro-one-param";
    wait-ms = <0>;
    tap-ms = <0>;
    #binding-cells = <1>;
    bindings
      = <&macro_param_1to1>
      , <&macro_press &kp MACRO_PLACEHOLDER>
      #ifdef LAYER_RightRingy
      , <&macro_press &mo LAYER_RightRingy>
      #endif
      , <&macro_pause_for_release>
      , <&macro_param_1to1>
      , <&macro_release &kp MACRO_PLACEHOLDER>
      #ifdef LAYER_RightRingy
      , <&macro_release &mo LAYER_RightRingy>
      #endif
      ;
  };
  right_ringy_tap: homey_right_ringy_tap {
    compatible = "zmk,behavior-macro-one-param";
    wait-ms = <0>;
    tap-ms = <0>;
    #binding-cells = <1>;
    bindings
      = <&macro_release
          &kp LSFT &kp RSFT
          &kp LALT &kp RALT
          &kp LCTL &kp RCTL
          &kp LGUI &kp RGUI>
      , <&macro_tap &kp RIGHT_RINGY_KEY>
      , <&macro_param_1to1>
      , <&macro_tap &kp MACRO_PLACEHOLDER>
      ;
  };
  #define RightRingy(key, layer_index) RightRingy_unroll(layer_index) (key)
  #define RightRingy_unroll(layer_index) RightRingy_concat(RightRingy_layer, layer_index)
  #define RightRingy_concat(prefix, layer_index) prefix ## layer_index
  #ifdef ENFORCE_BILATERAL
  #define right_ringy_layer0_variant right_ringy_bilateral
  #else
  #define right_ringy_layer0_variant right_ringy
  #endif
  #define RightRingy_layer0(key) right_ringy_layer0_variant RIGHT_RINGY_MOD key
  #define RightRingy_layer1(key) right_ringy RIGHT_RINGY_MOD key
  #define RightRingy_layer2(key) right_ringy RIGHT_RINGY_MOD key
  #define RightRingy_layer3(key) right_ringy RIGHT_RINGY_MOD key
  #define RightRingy_layer4(key) right_ringy RIGHT_RINGY_MOD key
  #define RightRingy_layer5(key) right_ringy RIGHT_RINGY_MOD key
  #define RightRingy_layer6(key) right_ringy RIGHT_RINGY_MOD key
  #define RightRingy_layer7(key) right_ringy RIGHT_RINGY_MOD key
  #ifndef LEFT_MIDDY_HOLDING_TYPE
  #define LEFT_MIDDY_HOLDING_TYPE MIDDY_HOLDING_TYPE
  #endif
  #ifndef LEFT_MIDDY_HOLDING_TIME
  #define LEFT_MIDDY_HOLDING_TIME MIDDY_HOLDING_TIME
  #endif
  #ifndef LEFT_MIDDY_STREAK_DECAY
  #define LEFT_MIDDY_STREAK_DECAY MIDDY_STREAK_DECAY
  #endif
  #ifndef LEFT_MIDDY_REPEAT_DECAY
  #define LEFT_MIDDY_REPEAT_DECAY MIDDY_REPEAT_DECAY
  #endif
  left_middy: homey_left_middy {
    compatible = "zmk,behavior-hold-tap";
    flavor = LEFT_MIDDY_HOLDING_TYPE;
    hold-trigger-key-positions = <RIGHT_HAND_KEYS THUMB_KEYS>;
    hold-trigger-on-release; // wait for other home row mods
    tapping-term-ms = <LEFT_MIDDY_HOLDING_TIME>;
    quick-tap-ms = <LEFT_MIDDY_REPEAT_DECAY>;
    require-prior-idle-ms = <LEFT_MIDDY_STREAK_DECAY>;
    #binding-cells = <2>;
    bindings = <&kp>, <&kp>;
  };
  left_middy_bilateral: homey_left_middy_bilateral {
    compatible = "zmk,behavior-hold-tap";
    flavor = LEFT_MIDDY_HOLDING_TYPE;
    hold-trigger-key-positions = <RIGHT_HAND_KEYS THUMB_KEYS>;
    hold-trigger-on-release; // wait for other home row mods
    tapping-term-ms = <LEFT_MIDDY_HOLDING_TIME>;
    quick-tap-ms = <LEFT_MIDDY_REPEAT_DECAY>;
    require-prior-idle-ms = <LEFT_MIDDY_STREAK_DECAY>;
    #binding-cells = <2>;
    bindings = <&left_middy_hold>, <&kp>;
  };
  left_middy_hold: homey_left_middy_hold {
    compatible = "zmk,behavior-macro-one-param";
    wait-ms = <0>;
    tap-ms = <0>;
    #binding-cells = <1>;
    bindings
      = <&macro_param_1to1>
      , <&macro_press &kp MACRO_PLACEHOLDER>
      #ifdef LAYER_LeftMiddy
      , <&macro_press &mo LAYER_LeftMiddy>
      #endif
      , <&macro_pause_for_release>
      , <&macro_param_1to1>
      , <&macro_release &kp MACRO_PLACEHOLDER>
      #ifdef LAYER_LeftMiddy
      , <&macro_release &mo LAYER_LeftMiddy>
      #endif
      ;
  };
  left_middy_tap: homey_left_middy_tap {
    compatible = "zmk,behavior-macro-one-param";
    wait-ms = <0>;
    tap-ms = <0>;
    #binding-cells = <1>;
    bindings
      = <&macro_release
          &kp LSFT &kp RSFT
          &kp LALT &kp RALT
          &kp LCTL &kp RCTL
          &kp LGUI &kp RGUI>
      , <&macro_tap &kp LEFT_MIDDY_KEY>
      , <&macro_param_1to1>
      , <&macro_tap &kp MACRO_PLACEHOLDER>
      ;
  };
  #define LeftMiddy(key, layer_index) LeftMiddy_unroll(layer_index) (key)
  #define LeftMiddy_unroll(layer_index) LeftMiddy_concat(LeftMiddy_layer, layer_index)
  #define LeftMiddy_concat(prefix, layer_index) prefix ## layer_index
  #ifdef ENFORCE_BILATERAL
  #define left_middy_layer0_variant left_middy_bilateral
  #else
  #define left_middy_layer0_variant left_middy
  #endif
  #define LeftMiddy_layer0(key) left_middy_layer0_variant LEFT_MIDDY_MOD key
  #define LeftMiddy_layer1(key) left_middy LEFT_MIDDY_MOD key
  #define LeftMiddy_layer2(key) left_middy LEFT_MIDDY_MOD key
  #define LeftMiddy_layer3(key) left_middy LEFT_MIDDY_MOD key
  #define LeftMiddy_layer4(key) left_middy LEFT_MIDDY_MOD key
  #define LeftMiddy_layer5(key) left_middy LEFT_MIDDY_MOD key
  #define LeftMiddy_layer6(key) left_middy LEFT_MIDDY_MOD key
  #define LeftMiddy_layer7(key) left_middy LEFT_MIDDY_MOD key
  #ifndef RIGHT_MIDDY_HOLDING_TYPE
  #define RIGHT_MIDDY_HOLDING_TYPE MIDDY_HOLDING_TYPE
  #endif
  #ifndef RIGHT_MIDDY_HOLDING_TIME
  #define RIGHT_MIDDY_HOLDING_TIME MIDDY_HOLDING_TIME
  #endif
  #ifndef RIGHT_MIDDY_STREAK_DECAY
  #define RIGHT_MIDDY_STREAK_DECAY MIDDY_STREAK_DECAY
  #endif
  #ifndef RIGHT_MIDDY_REPEAT_DECAY
  #define RIGHT_MIDDY_REPEAT_DECAY MIDDY_REPEAT_DECAY
  #endif
  right_middy: homey_right_middy {
    compatible = "zmk,behavior-hold-tap";
    flavor = RIGHT_MIDDY_HOLDING_TYPE;
    hold-trigger-key-positions = <LEFT_HAND_KEYS THUMB_KEYS>;
    hold-trigger-on-release; // wait for other home row mods
    tapping-term-ms = <RIGHT_MIDDY_HOLDING_TIME>;
    quick-tap-ms = <RIGHT_MIDDY_REPEAT_DECAY>;
    require-prior-idle-ms = <RIGHT_MIDDY_STREAK_DECAY>;
    #binding-cells = <2>;
    bindings = <&kp>, <&kp>;
  };
  right_middy_bilateral: homey_right_middy_bilateral {
    compatible = "zmk,behavior-hold-tap";
    flavor = RIGHT_MIDDY_HOLDING_TYPE;
    hold-trigger-key-positions = <LEFT_HAND_KEYS THUMB_KEYS>;
    hold-trigger-on-release; // wait for other home row mods
    tapping-term-ms = <RIGHT_MIDDY_HOLDING_TIME>;
    quick-tap-ms = <RIGHT_MIDDY_REPEAT_DECAY>;
    require-prior-idle-ms = <RIGHT_MIDDY_STREAK_DECAY>;
    #binding-cells = <2>;
    bindings = <&right_middy_hold>, <&kp>;
  };
  right_middy_hold: homey_right_middy_hold {
    compatible = "zmk,behavior-macro-one-param";
    wait-ms = <0>;
    tap-ms = <0>;
    #binding-cells = <1>;
    bindings
      = <&macro_param_1to1>
      , <&macro_press &kp MACRO_PLACEHOLDER>
      #ifdef LAYER_RightMiddy
      , <&macro_press &mo LAYER_RightMiddy>
      #endif
      , <&macro_pause_for_release>
      , <&macro_param_1to1>
      , <&macro_release &kp MACRO_PLACEHOLDER>
      #ifdef LAYER_RightMiddy
      , <&macro_release &mo LAYER_RightMiddy>
      #endif
      ;
  };
  right_middy_tap: homey_right_middy_tap {
    compatible = "zmk,behavior-macro-one-param";
    wait-ms = <0>;
    tap-ms = <0>;
    #binding-cells = <1>;
    bindings
      = <&macro_release
          &kp LSFT &kp RSFT
          &kp LALT &kp RALT
          &kp LCTL &kp RCTL
          &kp LGUI &kp RGUI>
      , <&macro_tap &kp RIGHT_MIDDY_KEY>
      , <&macro_param_1to1>
      , <&macro_tap &kp MACRO_PLACEHOLDER>
      ;
  };
  #define RightMiddy(key, layer_index) RightMiddy_unroll(layer_index) (key)
  #define RightMiddy_unroll(layer_index) RightMiddy_concat(RightMiddy_layer, layer_index)
  #define RightMiddy_concat(prefix, layer_index) prefix ## layer_index
  #ifdef ENFORCE_BILATERAL
  #define right_middy_layer0_variant right_middy_bilateral
  #else
  #define right_middy_layer0_variant right_middy
  #endif
  #define RightMiddy_layer0(key) right_middy_layer0_variant RIGHT_MIDDY_MOD key
  #define RightMiddy_layer1(key) right_middy RIGHT_MIDDY_MOD key
  #define RightMiddy_layer2(key) right_middy RIGHT_MIDDY_MOD key
  #define RightMiddy_layer3(key) right_middy RIGHT_MIDDY_MOD key
  #define RightMiddy_layer4(key) right_middy RIGHT_MIDDY_MOD key
  #define RightMiddy_layer5(key) right_middy RIGHT_MIDDY_MOD key
  #define RightMiddy_layer6(key) right_middy RIGHT_MIDDY_MOD key
  #define RightMiddy_layer7(key) right_middy RIGHT_MIDDY_MOD key
  #ifndef LEFT_INDEX_HOLDING_TYPE
  #define LEFT_INDEX_HOLDING_TYPE INDEX_HOLDING_TYPE
  #endif
  #ifndef LEFT_INDEX_HOLDING_TIME
  #define LEFT_INDEX_HOLDING_TIME INDEX_HOLDING_TIME
  #endif
  #ifndef LEFT_INDEX_STREAK_DECAY
  #define LEFT_INDEX_STREAK_DECAY INDEX_STREAK_DECAY
  #endif
  #ifndef LEFT_INDEX_REPEAT_DECAY
  #define LEFT_INDEX_REPEAT_DECAY INDEX_REPEAT_DECAY
  #endif
  left_index: homey_left_index {
    compatible = "zmk,behavior-hold-tap";
    flavor = LEFT_INDEX_HOLDING_TYPE;
    hold-trigger-key-positions = <RIGHT_HAND_KEYS THUMB_KEYS>;
    hold-trigger-on-release; // wait for other home row mods
    tapping-term-ms = <LEFT_INDEX_HOLDING_TIME>;
    quick-tap-ms = <LEFT_INDEX_REPEAT_DECAY>;
    require-prior-idle-ms = <LEFT_INDEX_STREAK_DECAY>;
    #binding-cells = <2>;
    bindings = <&kp>, <&kp>;
  };
  left_index_bilateral: homey_left_index_bilateral {
    compatible = "zmk,behavior-hold-tap";
    flavor = LEFT_INDEX_HOLDING_TYPE;
    hold-trigger-key-positions = <RIGHT_HAND_KEYS THUMB_KEYS>;
    hold-trigger-on-release; // wait for other home row mods
    tapping-term-ms = <LEFT_INDEX_HOLDING_TIME>;
    quick-tap-ms = <LEFT_INDEX_REPEAT_DECAY>;
    require-prior-idle-ms = <LEFT_INDEX_STREAK_DECAY>;
    #binding-cells = <2>;
    bindings = <&left_index_hold>, <&kp>;
  };
  left_index_hold: homey_left_index_hold {
    compatible = "zmk,behavior-macro-one-param";
    wait-ms = <0>;
    tap-ms = <0>;
    #binding-cells = <1>;
    bindings
      = <&macro_param_1to1>
      , <&macro_press &kp MACRO_PLACEHOLDER>
      #ifdef LAYER_LeftIndex
      , <&macro_press &mo LAYER_LeftIndex>
      #endif
      , <&macro_pause_for_release>
      , <&macro_param_1to1>
      , <&macro_release &kp MACRO_PLACEHOLDER>
      #ifdef LAYER_LeftIndex
      , <&macro_release &mo LAYER_LeftIndex>
      #endif
      ;
  };
  left_index_tap: homey_left_index_tap {
    compatible = "zmk,behavior-macro-one-param";
    wait-ms = <0>;
    tap-ms = <0>;
    #binding-cells = <1>;
    bindings
      = <&macro_release
          &kp LSFT &kp RSFT
          &kp LALT &kp RALT
          &kp LCTL &kp RCTL
          &kp LGUI &kp RGUI>
      , <&macro_tap &kp LEFT_INDEX_KEY>
      , <&macro_param_1to1>
      , <&macro_tap &kp MACRO_PLACEHOLDER>
      ;
  };
  #define LeftIndex(key, layer_index) LeftIndex_unroll(layer_index) (key)
  #define LeftIndex_unroll(layer_index) LeftIndex_concat(LeftIndex_layer, layer_index)
  #define LeftIndex_concat(prefix, layer_index) prefix ## layer_index
  #ifdef ENFORCE_BILATERAL
  #define left_index_layer0_variant left_index_bilateral
  #else
  #define left_index_layer0_variant left_index
  #endif
  #define LeftIndex_layer0(key) left_index_layer0_variant LEFT_INDEX_MOD key
  #define LeftIndex_layer1(key) left_index LEFT_INDEX_MOD key
  #define LeftIndex_layer2(key) left_index LEFT_INDEX_MOD key
  #define LeftIndex_layer3(key) left_index LEFT_INDEX_MOD key
  #define LeftIndex_layer4(key) left_index LEFT_INDEX_MOD key
  #define LeftIndex_layer5(key) left_index LEFT_INDEX_MOD key
  #define LeftIndex_layer6(key) left_index LEFT_INDEX_MOD key
  #define LeftIndex_layer7(key) left_index LEFT_INDEX_MOD key
  #ifndef RIGHT_INDEX_HOLDING_TYPE
  #define RIGHT_INDEX_HOLDING_TYPE INDEX_HOLDING_TYPE
  #endif
  #ifndef RIGHT_INDEX_HOLDING_TIME
  #define RIGHT_INDEX_HOLDING_TIME INDEX_HOLDING_TIME
  #endif
  #ifndef RIGHT_INDEX_STREAK_DECAY
  #define RIGHT_INDEX_STREAK_DECAY INDEX_STREAK_DECAY
  #endif
  #ifndef RIGHT_INDEX_REPEAT_DECAY
  #define RIGHT_INDEX_REPEAT_DECAY INDEX_REPEAT_DECAY
  #endif
  right_index: homey_right_index {
    compatible = "zmk,behavior-hold-tap";
    flavor = RIGHT_INDEX_HOLDING_TYPE;
    hold-trigger-key-positions = <LEFT_HAND_KEYS THUMB_KEYS>;
    hold-trigger-on-release; // wait for other home row mods
    tapping-term-ms = <RIGHT_INDEX_HOLDING_TIME>;
    quick-tap-ms = <RIGHT_INDEX_REPEAT_DECAY>;
    require-prior-idle-ms = <RIGHT_INDEX_STREAK_DECAY>;
    #binding-cells = <2>;
    bindings = <&kp>, <&kp>;
  };
  right_index_bilateral: homey_right_index_bilateral {
    compatible = "zmk,behavior-hold-tap";
    flavor = RIGHT_INDEX_HOLDING_TYPE;
    hold-trigger-key-positions = <LEFT_HAND_KEYS THUMB_KEYS>;
    hold-trigger-on-release; // wait for other home row mods
    tapping-term-ms = <RIGHT_INDEX_HOLDING_TIME>;
    quick-tap-ms = <RIGHT_INDEX_REPEAT_DECAY>;
    require-prior-idle-ms = <RIGHT_INDEX_STREAK_DECAY>;
    #binding-cells = <2>;
    bindings = <&right_index_hold>, <&kp>;
  };
  right_index_hold: homey_right_index_hold {
    compatible = "zmk,behavior-macro-one-param";
    wait-ms = <0>;
    tap-ms = <0>;
    #binding-cells = <1>;
    bindings
      = <&macro_param_1to1>
      , <&macro_press &kp MACRO_PLACEHOLDER>
      #ifdef LAYER_RightIndex
      , <&macro_press &mo LAYER_RightIndex>
      #endif
      , <&macro_pause_for_release>
      , <&macro_param_1to1>
      , <&macro_release &kp MACRO_PLACEHOLDER>
      #ifdef LAYER_RightIndex
      , <&macro_release &mo LAYER_RightIndex>
      #endif
      ;
  };
  right_index_tap: homey_right_index_tap {
    compatible = "zmk,behavior-macro-one-param";
    wait-ms = <0>;
    tap-ms = <0>;
    #binding-cells = <1>;
    bindings
      = <&macro_release
          &kp LSFT &kp RSFT
          &kp LALT &kp RALT
          &kp LCTL &kp RCTL
          &kp LGUI &kp RGUI>
      , <&macro_tap &kp RIGHT_INDEX_KEY>
      , <&macro_param_1to1>
      , <&macro_tap &kp MACRO_PLACEHOLDER>
      ;
  };
  #define RightIndex(key, layer_index) RightIndex_unroll(layer_index) (key)
  #define RightIndex_unroll(layer_index) RightIndex_concat(RightIndex_layer, layer_index)
  #define RightIndex_concat(prefix, layer_index) prefix ## layer_index
  #ifdef ENFORCE_BILATERAL
  #define right_index_layer0_variant right_index_bilateral
  #else
  #define right_index_layer0_variant right_index
  #endif
  #define RightIndex_layer0(key) right_index_layer0_variant RIGHT_INDEX_MOD key
  #define RightIndex_layer1(key) right_index RIGHT_INDEX_MOD key
  #define RightIndex_layer2(key) right_index RIGHT_INDEX_MOD key
  #define RightIndex_layer3(key) right_index RIGHT_INDEX_MOD key
  #define RightIndex_layer4(key) right_index RIGHT_INDEX_MOD key
  #define RightIndex_layer5(key) right_index RIGHT_INDEX_MOD key
  #define RightIndex_layer6(key) right_index RIGHT_INDEX_MOD key
  #define RightIndex_layer7(key) right_index RIGHT_INDEX_MOD key
  #ifndef LEFT_RINGY_PINKY_HOLDING_TYPE
  #define LEFT_RINGY_PINKY_HOLDING_TYPE LEFT_RINGY_CHORD_HOLDING_TYPE
  #endif
  #ifndef LEFT_RINGY_PINKY_HOLDING_TIME
  #define LEFT_RINGY_PINKY_HOLDING_TIME LEFT_RINGY_CHORD_HOLDING_TIME
  #endif
  #ifndef LEFT_RINGY_PINKY_STREAK_DECAY
  #define LEFT_RINGY_PINKY_STREAK_DECAY LEFT_RINGY_CHORD_STREAK_DECAY
  #endif
  #ifndef LEFT_RINGY_PINKY_REPEAT_DECAY
  #define LEFT_RINGY_PINKY_REPEAT_DECAY LEFT_RINGY_CHORD_REPEAT_DECAY
  #endif
  left_ringy_pinky: homey_left_ringy_pinky {
    compatible = "zmk,behavior-hold-tap";
    flavor = LEFT_RINGY_HOLDING_TYPE;
    hold-trigger-key-positions = <RIGHT_HAND_KEYS THUMB_KEYS>;
    hold-trigger-on-release; // wait for other home row mods
    tapping-term-ms = <LEFT_RINGY_HOLDING_TIME>;
    quick-tap-ms = <LEFT_RINGY_REPEAT_DECAY>;
    require-prior-idle-ms = <LEFT_RINGY_STREAK_DECAY>;
    #binding-cells = <2>;
    bindings = <&kp>, <&kp>;
  };
  left_ringy_pinky_bilateral: homey_left_ringy_pinky_bilateral {
    compatible = "zmk,behavior-hold-tap";
    flavor = LEFT_RINGY_HOLDING_TYPE;
    hold-trigger-key-positions = <RIGHT_HAND_KEYS THUMB_KEYS>;
    hold-trigger-on-release; // wait for other home row mods
    tapping-term-ms = <LEFT_RINGY_HOLDING_TIME>;
    quick-tap-ms = <LEFT_RINGY_REPEAT_DECAY>;
    require-prior-idle-ms = <LEFT_RINGY_STREAK_DECAY>;
    #binding-cells = <2>;
    bindings = <&kp>, <&left_ringy_tap>;
  };
  #define LeftRingyPinky left_ringy_pinky_bilateral LEFT_PINKY_MOD LEFT_PINKY_KEY
  #ifndef LEFT_MIDDY_PINKY_HOLDING_TYPE
  #define LEFT_MIDDY_PINKY_HOLDING_TYPE LEFT_MIDDY_CHORD_HOLDING_TYPE
  #endif
  #ifndef LEFT_MIDDY_PINKY_HOLDING_TIME
  #define LEFT_MIDDY_PINKY_HOLDING_TIME LEFT_MIDDY_CHORD_HOLDING_TIME
  #endif
  #ifndef LEFT_MIDDY_PINKY_STREAK_DECAY
  #define LEFT_MIDDY_PINKY_STREAK_DECAY LEFT_MIDDY_CHORD_STREAK_DECAY
  #endif
  #ifndef LEFT_MIDDY_PINKY_REPEAT_DECAY
  #define LEFT_MIDDY_PINKY_REPEAT_DECAY LEFT_MIDDY_CHORD_REPEAT_DECAY
  #endif
  left_middy_pinky: homey_left_middy_pinky {
    compatible = "zmk,behavior-hold-tap";
    flavor = LEFT_MIDDY_HOLDING_TYPE;
    hold-trigger-key-positions = <RIGHT_HAND_KEYS THUMB_KEYS>;
    hold-trigger-on-release; // wait for other home row mods
    tapping-term-ms = <LEFT_MIDDY_HOLDING_TIME>;
    quick-tap-ms = <LEFT_MIDDY_REPEAT_DECAY>;
    require-prior-idle-ms = <LEFT_MIDDY_STREAK_DECAY>;
    #binding-cells = <2>;
    bindings = <&kp>, <&kp>;
  };
  left_middy_pinky_bilateral: homey_left_middy_pinky_bilateral {
    compatible = "zmk,behavior-hold-tap";
    flavor = LEFT_MIDDY_HOLDING_TYPE;
    hold-trigger-key-positions = <RIGHT_HAND_KEYS THUMB_KEYS>;
    hold-trigger-on-release; // wait for other home row mods
    tapping-term-ms = <LEFT_MIDDY_HOLDING_TIME>;
    quick-tap-ms = <LEFT_MIDDY_REPEAT_DECAY>;
    require-prior-idle-ms = <LEFT_MIDDY_STREAK_DECAY>;
    #binding-cells = <2>;
    bindings = <&kp>, <&left_middy_tap>;
  };
  #define LeftMiddyPinky left_middy_pinky_bilateral LEFT_PINKY_MOD LEFT_PINKY_KEY
  #ifndef LEFT_INDEX_PINKY_HOLDING_TYPE
  #define LEFT_INDEX_PINKY_HOLDING_TYPE LEFT_INDEX_CHORD_HOLDING_TYPE
  #endif
  #ifndef LEFT_INDEX_PINKY_HOLDING_TIME
  #define LEFT_INDEX_PINKY_HOLDING_TIME LEFT_INDEX_CHORD_HOLDING_TIME
  #endif
  #ifndef LEFT_INDEX_PINKY_STREAK_DECAY
  #define LEFT_INDEX_PINKY_STREAK_DECAY LEFT_INDEX_CHORD_STREAK_DECAY
  #endif
  #ifndef LEFT_INDEX_PINKY_REPEAT_DECAY
  #define LEFT_INDEX_PINKY_REPEAT_DECAY LEFT_INDEX_CHORD_REPEAT_DECAY
  #endif
  left_index_pinky: homey_left_index_pinky {
    compatible = "zmk,behavior-hold-tap";
    flavor = LEFT_INDEX_HOLDING_TYPE;
    hold-trigger-key-positions = <RIGHT_HAND_KEYS THUMB_KEYS>;
    hold-trigger-on-release; // wait for other home row mods
    tapping-term-ms = <LEFT_INDEX_HOLDING_TIME>;
    quick-tap-ms = <LEFT_INDEX_REPEAT_DECAY>;
    require-prior-idle-ms = <LEFT_INDEX_STREAK_DECAY>;
    #binding-cells = <2>;
    bindings = <&kp>, <&kp>;
  };
  left_index_pinky_bilateral: homey_left_index_pinky_bilateral {
    compatible = "zmk,behavior-hold-tap";
    flavor = LEFT_INDEX_HOLDING_TYPE;
    hold-trigger-key-positions = <RIGHT_HAND_KEYS THUMB_KEYS>;
    hold-trigger-on-release; // wait for other home row mods
    tapping-term-ms = <LEFT_INDEX_HOLDING_TIME>;
    quick-tap-ms = <LEFT_INDEX_REPEAT_DECAY>;
    require-prior-idle-ms = <LEFT_INDEX_STREAK_DECAY>;
    #binding-cells = <2>;
    bindings = <&kp>, <&left_index_tap>;
  };
  #define LeftIndexPinky left_index_pinky_bilateral LEFT_PINKY_MOD LEFT_PINKY_KEY
  #ifndef RIGHT_RINGY_PINKY_HOLDING_TYPE
  #define RIGHT_RINGY_PINKY_HOLDING_TYPE RIGHT_RINGY_CHORD_HOLDING_TYPE
  #endif
  #ifndef RIGHT_RINGY_PINKY_HOLDING_TIME
  #define RIGHT_RINGY_PINKY_HOLDING_TIME RIGHT_RINGY_CHORD_HOLDING_TIME
  #endif
  #ifndef RIGHT_RINGY_PINKY_STREAK_DECAY
  #define RIGHT_RINGY_PINKY_STREAK_DECAY RIGHT_RINGY_CHORD_STREAK_DECAY
  #endif
  #ifndef RIGHT_RINGY_PINKY_REPEAT_DECAY
  #define RIGHT_RINGY_PINKY_REPEAT_DECAY RIGHT_RINGY_CHORD_REPEAT_DECAY
  #endif
  right_ringy_pinky: homey_right_ringy_pinky {
    compatible = "zmk,behavior-hold-tap";
    flavor = RIGHT_RINGY_HOLDING_TYPE;
    hold-trigger-key-positions = <LEFT_HAND_KEYS THUMB_KEYS>;
    hold-trigger-on-release; // wait for other home row mods
    tapping-term-ms = <RIGHT_RINGY_HOLDING_TIME>;
    quick-tap-ms = <RIGHT_RINGY_REPEAT_DECAY>;
    require-prior-idle-ms = <RIGHT_RINGY_STREAK_DECAY>;
    #binding-cells = <2>;
    bindings = <&kp>, <&kp>;
  };
  right_ringy_pinky_bilateral: homey_right_ringy_pinky_bilateral {
    compatible = "zmk,behavior-hold-tap";
    flavor = RIGHT_RINGY_HOLDING_TYPE;
    hold-trigger-key-positions = <LEFT_HAND_KEYS THUMB_KEYS>;
    hold-trigger-on-release; // wait for other home row mods
    tapping-term-ms = <RIGHT_RINGY_HOLDING_TIME>;
    quick-tap-ms = <RIGHT_RINGY_REPEAT_DECAY>;
    require-prior-idle-ms = <RIGHT_RINGY_STREAK_DECAY>;
    #binding-cells = <2>;
    bindings = <&kp>, <&right_ringy_tap>;
  };
  #define RightRingyPinky right_ringy_pinky_bilateral RIGHT_PINKY_MOD RIGHT_PINKY_KEY
  #ifndef RIGHT_MIDDY_PINKY_HOLDING_TYPE
  #define RIGHT_MIDDY_PINKY_HOLDING_TYPE RIGHT_MIDDY_CHORD_HOLDING_TYPE
  #endif
  #ifndef RIGHT_MIDDY_PINKY_HOLDING_TIME
  #define RIGHT_MIDDY_PINKY_HOLDING_TIME RIGHT_MIDDY_CHORD_HOLDING_TIME
  #endif
  #ifndef RIGHT_MIDDY_PINKY_STREAK_DECAY
  #define RIGHT_MIDDY_PINKY_STREAK_DECAY RIGHT_MIDDY_CHORD_STREAK_DECAY
  #endif
  #ifndef RIGHT_MIDDY_PINKY_REPEAT_DECAY
  #define RIGHT_MIDDY_PINKY_REPEAT_DECAY RIGHT_MIDDY_CHORD_REPEAT_DECAY
  #endif
  right_middy_pinky: homey_right_middy_pinky {
    compatible = "zmk,behavior-hold-tap";
    flavor = RIGHT_MIDDY_HOLDING_TYPE;
    hold-trigger-key-positions = <LEFT_HAND_KEYS THUMB_KEYS>;
    hold-trigger-on-release; // wait for other home row mods
    tapping-term-ms = <RIGHT_MIDDY_HOLDING_TIME>;
    quick-tap-ms = <RIGHT_MIDDY_REPEAT_DECAY>;
    require-prior-idle-ms = <RIGHT_MIDDY_STREAK_DECAY>;
    #binding-cells = <2>;
    bindings = <&kp>, <&kp>;
  };
  right_middy_pinky_bilateral: homey_right_middy_pinky_bilateral {
    compatible = "zmk,behavior-hold-tap";
    flavor = RIGHT_MIDDY_HOLDING_TYPE;
    hold-trigger-key-positions = <LEFT_HAND_KEYS THUMB_KEYS>;
    hold-trigger-on-release; // wait for other home row mods
    tapping-term-ms = <RIGHT_MIDDY_HOLDING_TIME>;
    quick-tap-ms = <RIGHT_MIDDY_REPEAT_DECAY>;
    require-prior-idle-ms = <RIGHT_MIDDY_STREAK_DECAY>;
    #binding-cells = <2>;
    bindings = <&kp>, <&right_middy_tap>;
  };
  #define RightMiddyPinky right_middy_pinky_bilateral RIGHT_PINKY_MOD RIGHT_PINKY_KEY
  #ifndef RIGHT_INDEX_PINKY_HOLDING_TYPE
  #define RIGHT_INDEX_PINKY_HOLDING_TYPE RIGHT_INDEX_CHORD_HOLDING_TYPE
  #endif
  #ifndef RIGHT_INDEX_PINKY_HOLDING_TIME
  #define RIGHT_INDEX_PINKY_HOLDING_TIME RIGHT_INDEX_CHORD_HOLDING_TIME
  #endif
  #ifndef RIGHT_INDEX_PINKY_STREAK_DECAY
  #define RIGHT_INDEX_PINKY_STREAK_DECAY RIGHT_INDEX_CHORD_STREAK_DECAY
  #endif
  #ifndef RIGHT_INDEX_PINKY_REPEAT_DECAY
  #define RIGHT_INDEX_PINKY_REPEAT_DECAY RIGHT_INDEX_CHORD_REPEAT_DECAY
  #endif
  right_index_pinky: homey_right_index_pinky {
    compatible = "zmk,behavior-hold-tap";
    flavor = RIGHT_INDEX_HOLDING_TYPE;
    hold-trigger-key-positions = <LEFT_HAND_KEYS THUMB_KEYS>;
    hold-trigger-on-release; // wait for other home row mods
    tapping-term-ms = <RIGHT_INDEX_HOLDING_TIME>;
    quick-tap-ms = <RIGHT_INDEX_REPEAT_DECAY>;
    require-prior-idle-ms = <RIGHT_INDEX_STREAK_DECAY>;
    #binding-cells = <2>;
    bindings = <&kp>, <&kp>;
  };
  right_index_pinky_bilateral: homey_right_index_pinky_bilateral {
    compatible = "zmk,behavior-hold-tap";
    flavor = RIGHT_INDEX_HOLDING_TYPE;
    hold-trigger-key-positions = <LEFT_HAND_KEYS THUMB_KEYS>;
    hold-trigger-on-release; // wait for other home row mods
    tapping-term-ms = <RIGHT_INDEX_HOLDING_TIME>;
    quick-tap-ms = <RIGHT_INDEX_REPEAT_DECAY>;
    require-prior-idle-ms = <RIGHT_INDEX_STREAK_DECAY>;
    #binding-cells = <2>;
    bindings = <&kp>, <&right_index_tap>;
  };
  #define RightIndexPinky right_index_pinky_bilateral RIGHT_PINKY_MOD RIGHT_PINKY_KEY
  #ifndef LEFT_PINKY_RINGY_HOLDING_TYPE
  #define LEFT_PINKY_RINGY_HOLDING_TYPE LEFT_PINKY_CHORD_HOLDING_TYPE
  #endif
  #ifndef LEFT_PINKY_RINGY_HOLDING_TIME
  #define LEFT_PINKY_RINGY_HOLDING_TIME LEFT_PINKY_CHORD_HOLDING_TIME
  #endif
  #ifndef LEFT_PINKY_RINGY_STREAK_DECAY
  #define LEFT_PINKY_RINGY_STREAK_DECAY LEFT_PINKY_CHORD_STREAK_DECAY
  #endif
  #ifndef LEFT_PINKY_RINGY_REPEAT_DECAY
  #define LEFT_PINKY_RINGY_REPEAT_DECAY LEFT_PINKY_CHORD_REPEAT_DECAY
  #endif
  left_pinky_ringy: homey_left_pinky_ringy {
    compatible = "zmk,behavior-hold-tap";
    flavor = LEFT_PINKY_HOLDING_TYPE;
    hold-trigger-key-positions = <RIGHT_HAND_KEYS THUMB_KEYS>;
    hold-trigger-on-release; // wait for other home row mods
    tapping-term-ms = <LEFT_PINKY_HOLDING_TIME>;
    quick-tap-ms = <LEFT_PINKY_REPEAT_DECAY>;
    require-prior-idle-ms = <LEFT_PINKY_STREAK_DECAY>;
    #binding-cells = <2>;
    bindings = <&kp>, <&kp>;
  };
  left_pinky_ringy_bilateral: homey_left_pinky_ringy_bilateral {
    compatible = "zmk,behavior-hold-tap";
    flavor = LEFT_PINKY_HOLDING_TYPE;
    hold-trigger-key-positions = <RIGHT_HAND_KEYS THUMB_KEYS>;
    hold-trigger-on-release; // wait for other home row mods
    tapping-term-ms = <LEFT_PINKY_HOLDING_TIME>;
    quick-tap-ms = <LEFT_PINKY_REPEAT_DECAY>;
    require-prior-idle-ms = <LEFT_PINKY_STREAK_DECAY>;
    #binding-cells = <2>;
    bindings = <&kp>, <&left_pinky_tap>;
  };
  #define LeftPinkyRingy left_pinky_ringy_bilateral LEFT_RINGY_MOD LEFT_RINGY_KEY
  #ifndef LEFT_MIDDY_RINGY_HOLDING_TYPE
  #define LEFT_MIDDY_RINGY_HOLDING_TYPE LEFT_MIDDY_CHORD_HOLDING_TYPE
  #endif
  #ifndef LEFT_MIDDY_RINGY_HOLDING_TIME
  #define LEFT_MIDDY_RINGY_HOLDING_TIME LEFT_MIDDY_CHORD_HOLDING_TIME
  #endif
  #ifndef LEFT_MIDDY_RINGY_STREAK_DECAY
  #define LEFT_MIDDY_RINGY_STREAK_DECAY LEFT_MIDDY_CHORD_STREAK_DECAY
  #endif
  #ifndef LEFT_MIDDY_RINGY_REPEAT_DECAY
  #define LEFT_MIDDY_RINGY_REPEAT_DECAY LEFT_MIDDY_CHORD_REPEAT_DECAY
  #endif
  left_middy_ringy: homey_left_middy_ringy {
    compatible = "zmk,behavior-hold-tap";
    flavor = LEFT_MIDDY_HOLDING_TYPE;
    hold-trigger-key-positions = <RIGHT_HAND_KEYS THUMB_KEYS>;
    hold-trigger-on-release; // wait for other home row mods
    tapping-term-ms = <LEFT_MIDDY_HOLDING_TIME>;
    quick-tap-ms = <LEFT_MIDDY_REPEAT_DECAY>;
    require-prior-idle-ms = <LEFT_MIDDY_STREAK_DECAY>;
    #binding-cells = <2>;
    bindings = <&kp>, <&kp>;
  };
  left_middy_ringy_bilateral: homey_left_middy_ringy_bilateral {
    compatible = "zmk,behavior-hold-tap";
    flavor = LEFT_MIDDY_HOLDING_TYPE;
    hold-trigger-key-positions = <RIGHT_HAND_KEYS THUMB_KEYS>;
    hold-trigger-on-release; // wait for other home row mods
    tapping-term-ms = <LEFT_MIDDY_HOLDING_TIME>;
    quick-tap-ms = <LEFT_MIDDY_REPEAT_DECAY>;
    require-prior-idle-ms = <LEFT_MIDDY_STREAK_DECAY>;
    #binding-cells = <2>;
    bindings = <&kp>, <&left_middy_tap>;
  };
  #define LeftMiddyRingy left_middy_ringy_bilateral LEFT_RINGY_MOD LEFT_RINGY_KEY
  #ifndef LEFT_INDEX_RINGY_HOLDING_TYPE
  #define LEFT_INDEX_RINGY_HOLDING_TYPE LEFT_INDEX_CHORD_HOLDING_TYPE
  #endif
  #ifndef LEFT_INDEX_RINGY_HOLDING_TIME
  #define LEFT_INDEX_RINGY_HOLDING_TIME LEFT_INDEX_CHORD_HOLDING_TIME
  #endif
  #ifndef LEFT_INDEX_RINGY_STREAK_DECAY
  #define LEFT_INDEX_RINGY_STREAK_DECAY LEFT_INDEX_CHORD_STREAK_DECAY
  #endif
  #ifndef LEFT_INDEX_RINGY_REPEAT_DECAY
  #define LEFT_INDEX_RINGY_REPEAT_DECAY LEFT_INDEX_CHORD_REPEAT_DECAY
  #endif
  left_index_ringy: homey_left_index_ringy {
    compatible = "zmk,behavior-hold-tap";
    flavor = LEFT_INDEX_HOLDING_TYPE;
    hold-trigger-key-positions = <RIGHT_HAND_KEYS THUMB_KEYS>;
    hold-trigger-on-release; // wait for other home row mods
    tapping-term-ms = <LEFT_INDEX_HOLDING_TIME>;
    quick-tap-ms = <LEFT_INDEX_REPEAT_DECAY>;
    require-prior-idle-ms = <LEFT_INDEX_STREAK_DECAY>;
    #binding-cells = <2>;
    bindings = <&kp>, <&kp>;
  };
  left_index_ringy_bilateral: homey_left_index_ringy_bilateral {
    compatible = "zmk,behavior-hold-tap";
    flavor = LEFT_INDEX_HOLDING_TYPE;
    hold-trigger-key-positions = <RIGHT_HAND_KEYS THUMB_KEYS>;
    hold-trigger-on-release; // wait for other home row mods
    tapping-term-ms = <LEFT_INDEX_HOLDING_TIME>;
    quick-tap-ms = <LEFT_INDEX_REPEAT_DECAY>;
    require-prior-idle-ms = <LEFT_INDEX_STREAK_DECAY>;
    #binding-cells = <2>;
    bindings = <&kp>, <&left_index_tap>;
  };
  #define LeftIndexRingy left_index_ringy_bilateral LEFT_RINGY_MOD LEFT_RINGY_KEY
  #ifndef RIGHT_PINKY_RINGY_HOLDING_TYPE
  #define RIGHT_PINKY_RINGY_HOLDING_TYPE RIGHT_PINKY_CHORD_HOLDING_TYPE
  #endif
  #ifndef RIGHT_PINKY_RINGY_HOLDING_TIME
  #define RIGHT_PINKY_RINGY_HOLDING_TIME RIGHT_PINKY_CHORD_HOLDING_TIME
  #endif
  #ifndef RIGHT_PINKY_RINGY_STREAK_DECAY
  #define RIGHT_PINKY_RINGY_STREAK_DECAY RIGHT_PINKY_CHORD_STREAK_DECAY
  #endif
  #ifndef RIGHT_PINKY_RINGY_REPEAT_DECAY
  #define RIGHT_PINKY_RINGY_REPEAT_DECAY RIGHT_PINKY_CHORD_REPEAT_DECAY
  #endif
  right_pinky_ringy: homey_right_pinky_ringy {
    compatible = "zmk,behavior-hold-tap";
    flavor = RIGHT_PINKY_HOLDING_TYPE;
    hold-trigger-key-positions = <LEFT_HAND_KEYS THUMB_KEYS>;
    hold-trigger-on-release; // wait for other home row mods
    tapping-term-ms = <RIGHT_PINKY_HOLDING_TIME>;
    quick-tap-ms = <RIGHT_PINKY_REPEAT_DECAY>;
    require-prior-idle-ms = <RIGHT_PINKY_STREAK_DECAY>;
    #binding-cells = <2>;
    bindings = <&kp>, <&kp>;
  };
  right_pinky_ringy_bilateral: homey_right_pinky_ringy_bilateral {
    compatible = "zmk,behavior-hold-tap";
    flavor = RIGHT_PINKY_HOLDING_TYPE;
    hold-trigger-key-positions = <LEFT_HAND_KEYS THUMB_KEYS>;
    hold-trigger-on-release; // wait for other home row mods
    tapping-term-ms = <RIGHT_PINKY_HOLDING_TIME>;
    quick-tap-ms = <RIGHT_PINKY_REPEAT_DECAY>;
    require-prior-idle-ms = <RIGHT_PINKY_STREAK_DECAY>;
    #binding-cells = <2>;
    bindings = <&kp>, <&right_pinky_tap>;
  };
  #define RightPinkyRingy right_pinky_ringy_bilateral RIGHT_RINGY_MOD RIGHT_RINGY_KEY
  #ifndef RIGHT_MIDDY_RINGY_HOLDING_TYPE
  #define RIGHT_MIDDY_RINGY_HOLDING_TYPE RIGHT_MIDDY_CHORD_HOLDING_TYPE
  #endif
  #ifndef RIGHT_MIDDY_RINGY_HOLDING_TIME
  #define RIGHT_MIDDY_RINGY_HOLDING_TIME RIGHT_MIDDY_CHORD_HOLDING_TIME
  #endif
  #ifndef RIGHT_MIDDY_RINGY_STREAK_DECAY
  #define RIGHT_MIDDY_RINGY_STREAK_DECAY RIGHT_MIDDY_CHORD_STREAK_DECAY
  #endif
  #ifndef RIGHT_MIDDY_RINGY_REPEAT_DECAY
  #define RIGHT_MIDDY_RINGY_REPEAT_DECAY RIGHT_MIDDY_CHORD_REPEAT_DECAY
  #endif
  right_middy_ringy: homey_right_middy_ringy {
    compatible = "zmk,behavior-hold-tap";
    flavor = RIGHT_MIDDY_HOLDING_TYPE;
    hold-trigger-key-positions = <LEFT_HAND_KEYS THUMB_KEYS>;
    hold-trigger-on-release; // wait for other home row mods
    tapping-term-ms = <RIGHT_MIDDY_HOLDING_TIME>;
    quick-tap-ms = <RIGHT_MIDDY_REPEAT_DECAY>;
    require-prior-idle-ms = <RIGHT_MIDDY_STREAK_DECAY>;
    #binding-cells = <2>;
    bindings = <&kp>, <&kp>;
  };
  right_middy_ringy_bilateral: homey_right_middy_ringy_bilateral {
    compatible = "zmk,behavior-hold-tap";
    flavor = RIGHT_MIDDY_HOLDING_TYPE;
    hold-trigger-key-positions = <LEFT_HAND_KEYS THUMB_KEYS>;
    hold-trigger-on-release; // wait for other home row mods
    tapping-term-ms = <RIGHT_MIDDY_HOLDING_TIME>;
    quick-tap-ms = <RIGHT_MIDDY_REPEAT_DECAY>;
    require-prior-idle-ms = <RIGHT_MIDDY_STREAK_DECAY>;
    #binding-cells = <2>;
    bindings = <&kp>, <&right_middy_tap>;
  };
  #define RightMiddyRingy right_middy_ringy_bilateral RIGHT_RINGY_MOD RIGHT_RINGY_KEY
  #ifndef RIGHT_INDEX_RINGY_HOLDING_TYPE
  #define RIGHT_INDEX_RINGY_HOLDING_TYPE RIGHT_INDEX_CHORD_HOLDING_TYPE
  #endif
  #ifndef RIGHT_INDEX_RINGY_HOLDING_TIME
  #define RIGHT_INDEX_RINGY_HOLDING_TIME RIGHT_INDEX_CHORD_HOLDING_TIME
  #endif
  #ifndef RIGHT_INDEX_RINGY_STREAK_DECAY
  #define RIGHT_INDEX_RINGY_STREAK_DECAY RIGHT_INDEX_CHORD_STREAK_DECAY
  #endif
  #ifndef RIGHT_INDEX_RINGY_REPEAT_DECAY
  #define RIGHT_INDEX_RINGY_REPEAT_DECAY RIGHT_INDEX_CHORD_REPEAT_DECAY
  #endif
  right_index_ringy: homey_right_index_ringy {
    compatible = "zmk,behavior-hold-tap";
    flavor = RIGHT_INDEX_HOLDING_TYPE;
    hold-trigger-key-positions = <LEFT_HAND_KEYS THUMB_KEYS>;
    hold-trigger-on-release; // wait for other home row mods
    tapping-term-ms = <RIGHT_INDEX_HOLDING_TIME>;
    quick-tap-ms = <RIGHT_INDEX_REPEAT_DECAY>;
    require-prior-idle-ms = <RIGHT_INDEX_STREAK_DECAY>;
    #binding-cells = <2>;
    bindings = <&kp>, <&kp>;
  };
  right_index_ringy_bilateral: homey_right_index_ringy_bilateral {
    compatible = "zmk,behavior-hold-tap";
    flavor = RIGHT_INDEX_HOLDING_TYPE;
    hold-trigger-key-positions = <LEFT_HAND_KEYS THUMB_KEYS>;
    hold-trigger-on-release; // wait for other home row mods
    tapping-term-ms = <RIGHT_INDEX_HOLDING_TIME>;
    quick-tap-ms = <RIGHT_INDEX_REPEAT_DECAY>;
    require-prior-idle-ms = <RIGHT_INDEX_STREAK_DECAY>;
    #binding-cells = <2>;
    bindings = <&kp>, <&right_index_tap>;
  };
  #define RightIndexRingy right_index_ringy_bilateral RIGHT_RINGY_MOD RIGHT_RINGY_KEY
  #ifndef LEFT_PINKY_MIDDY_HOLDING_TYPE
  #define LEFT_PINKY_MIDDY_HOLDING_TYPE LEFT_PINKY_CHORD_HOLDING_TYPE
  #endif
  #ifndef LEFT_PINKY_MIDDY_HOLDING_TIME
  #define LEFT_PINKY_MIDDY_HOLDING_TIME LEFT_PINKY_CHORD_HOLDING_TIME
  #endif
  #ifndef LEFT_PINKY_MIDDY_STREAK_DECAY
  #define LEFT_PINKY_MIDDY_STREAK_DECAY LEFT_PINKY_CHORD_STREAK_DECAY
  #endif
  #ifndef LEFT_PINKY_MIDDY_REPEAT_DECAY
  #define LEFT_PINKY_MIDDY_REPEAT_DECAY LEFT_PINKY_CHORD_REPEAT_DECAY
  #endif
  left_pinky_middy: homey_left_pinky_middy {
    compatible = "zmk,behavior-hold-tap";
    flavor = LEFT_PINKY_HOLDING_TYPE;
    hold-trigger-key-positions = <RIGHT_HAND_KEYS THUMB_KEYS>;
    hold-trigger-on-release; // wait for other home row mods
    tapping-term-ms = <LEFT_PINKY_HOLDING_TIME>;
    quick-tap-ms = <LEFT_PINKY_REPEAT_DECAY>;
    require-prior-idle-ms = <LEFT_PINKY_STREAK_DECAY>;
    #binding-cells = <2>;
    bindings = <&kp>, <&kp>;
  };
  left_pinky_middy_bilateral: homey_left_pinky_middy_bilateral {
    compatible = "zmk,behavior-hold-tap";
    flavor = LEFT_PINKY_HOLDING_TYPE;
    hold-trigger-key-positions = <RIGHT_HAND_KEYS THUMB_KEYS>;
    hold-trigger-on-release; // wait for other home row mods
    tapping-term-ms = <LEFT_PINKY_HOLDING_TIME>;
    quick-tap-ms = <LEFT_PINKY_REPEAT_DECAY>;
    require-prior-idle-ms = <LEFT_PINKY_STREAK_DECAY>;
    #binding-cells = <2>;
    bindings = <&kp>, <&left_pinky_tap>;
  };
  #define LeftPinkyMiddy left_pinky_middy_bilateral LEFT_MIDDY_MOD LEFT_MIDDY_KEY
  #ifndef LEFT_RINGY_MIDDY_HOLDING_TYPE
  #define LEFT_RINGY_MIDDY_HOLDING_TYPE LEFT_RINGY_CHORD_HOLDING_TYPE
  #endif
  #ifndef LEFT_RINGY_MIDDY_HOLDING_TIME
  #define LEFT_RINGY_MIDDY_HOLDING_TIME LEFT_RINGY_CHORD_HOLDING_TIME
  #endif
  #ifndef LEFT_RINGY_MIDDY_STREAK_DECAY
  #define LEFT_RINGY_MIDDY_STREAK_DECAY LEFT_RINGY_CHORD_STREAK_DECAY
  #endif
  #ifndef LEFT_RINGY_MIDDY_REPEAT_DECAY
  #define LEFT_RINGY_MIDDY_REPEAT_DECAY LEFT_RINGY_CHORD_REPEAT_DECAY
  #endif
  left_ringy_middy: homey_left_ringy_middy {
    compatible = "zmk,behavior-hold-tap";
    flavor = LEFT_RINGY_HOLDING_TYPE;
    hold-trigger-key-positions = <RIGHT_HAND_KEYS THUMB_KEYS>;
    hold-trigger-on-release; // wait for other home row mods
    tapping-term-ms = <LEFT_RINGY_HOLDING_TIME>;
    quick-tap-ms = <LEFT_RINGY_REPEAT_DECAY>;
    require-prior-idle-ms = <LEFT_RINGY_STREAK_DECAY>;
    #binding-cells = <2>;
    bindings = <&kp>, <&kp>;
  };
  left_ringy_middy_bilateral: homey_left_ringy_middy_bilateral {
    compatible = "zmk,behavior-hold-tap";
    flavor = LEFT_RINGY_HOLDING_TYPE;
    hold-trigger-key-positions = <RIGHT_HAND_KEYS THUMB_KEYS>;
    hold-trigger-on-release; // wait for other home row mods
    tapping-term-ms = <LEFT_RINGY_HOLDING_TIME>;
    quick-tap-ms = <LEFT_RINGY_REPEAT_DECAY>;
    require-prior-idle-ms = <LEFT_RINGY_STREAK_DECAY>;
    #binding-cells = <2>;
    bindings = <&kp>, <&left_ringy_tap>;
  };
  #define LeftRingyMiddy left_ringy_middy_bilateral LEFT_MIDDY_MOD LEFT_MIDDY_KEY
  #ifndef LEFT_INDEX_MIDDY_HOLDING_TYPE
  #define LEFT_INDEX_MIDDY_HOLDING_TYPE LEFT_INDEX_CHORD_HOLDING_TYPE
  #endif
  #ifndef LEFT_INDEX_MIDDY_HOLDING_TIME
  #define LEFT_INDEX_MIDDY_HOLDING_TIME LEFT_INDEX_CHORD_HOLDING_TIME
  #endif
  #ifndef LEFT_INDEX_MIDDY_STREAK_DECAY
  #define LEFT_INDEX_MIDDY_STREAK_DECAY LEFT_INDEX_CHORD_STREAK_DECAY
  #endif
  #ifndef LEFT_INDEX_MIDDY_REPEAT_DECAY
  #define LEFT_INDEX_MIDDY_REPEAT_DECAY LEFT_INDEX_CHORD_REPEAT_DECAY
  #endif
  left_index_middy: homey_left_index_middy {
    compatible = "zmk,behavior-hold-tap";
    flavor = LEFT_INDEX_HOLDING_TYPE;
    hold-trigger-key-positions = <RIGHT_HAND_KEYS THUMB_KEYS>;
    hold-trigger-on-release; // wait for other home row mods
    tapping-term-ms = <LEFT_INDEX_HOLDING_TIME>;
    quick-tap-ms = <LEFT_INDEX_REPEAT_DECAY>;
    require-prior-idle-ms = <LEFT_INDEX_STREAK_DECAY>;
    #binding-cells = <2>;
    bindings = <&kp>, <&kp>;
  };
  left_index_middy_bilateral: homey_left_index_middy_bilateral {
    compatible = "zmk,behavior-hold-tap";
    flavor = LEFT_INDEX_HOLDING_TYPE;
    hold-trigger-key-positions = <RIGHT_HAND_KEYS THUMB_KEYS>;
    hold-trigger-on-release; // wait for other home row mods
    tapping-term-ms = <LEFT_INDEX_HOLDING_TIME>;
    quick-tap-ms = <LEFT_INDEX_REPEAT_DECAY>;
    require-prior-idle-ms = <LEFT_INDEX_STREAK_DECAY>;
    #binding-cells = <2>;
    bindings = <&kp>, <&left_index_tap>;
  };
  #define LeftIndexMiddy left_index_middy_bilateral LEFT_MIDDY_MOD LEFT_MIDDY_KEY
  #ifndef RIGHT_PINKY_MIDDY_HOLDING_TYPE
  #define RIGHT_PINKY_MIDDY_HOLDING_TYPE RIGHT_PINKY_CHORD_HOLDING_TYPE
  #endif
  #ifndef RIGHT_PINKY_MIDDY_HOLDING_TIME
  #define RIGHT_PINKY_MIDDY_HOLDING_TIME RIGHT_PINKY_CHORD_HOLDING_TIME
  #endif
  #ifndef RIGHT_PINKY_MIDDY_STREAK_DECAY
  #define RIGHT_PINKY_MIDDY_STREAK_DECAY RIGHT_PINKY_CHORD_STREAK_DECAY
  #endif
  #ifndef RIGHT_PINKY_MIDDY_REPEAT_DECAY
  #define RIGHT_PINKY_MIDDY_REPEAT_DECAY RIGHT_PINKY_CHORD_REPEAT_DECAY
  #endif
  right_pinky_middy: homey_right_pinky_middy {
    compatible = "zmk,behavior-hold-tap";
    flavor = RIGHT_PINKY_HOLDING_TYPE;
    hold-trigger-key-positions = <LEFT_HAND_KEYS THUMB_KEYS>;
    hold-trigger-on-release; // wait for other home row mods
    tapping-term-ms = <RIGHT_PINKY_HOLDING_TIME>;
    quick-tap-ms = <RIGHT_PINKY_REPEAT_DECAY>;
    require-prior-idle-ms = <RIGHT_PINKY_STREAK_DECAY>;
    #binding-cells = <2>;
    bindings = <&kp>, <&kp>;
  };
  right_pinky_middy_bilateral: homey_right_pinky_middy_bilateral {
    compatible = "zmk,behavior-hold-tap";
    flavor = RIGHT_PINKY_HOLDING_TYPE;
    hold-trigger-key-positions = <LEFT_HAND_KEYS THUMB_KEYS>;
    hold-trigger-on-release; // wait for other home row mods
    tapping-term-ms = <RIGHT_PINKY_HOLDING_TIME>;
    quick-tap-ms = <RIGHT_PINKY_REPEAT_DECAY>;
    require-prior-idle-ms = <RIGHT_PINKY_STREAK_DECAY>;
    #binding-cells = <2>;
    bindings = <&kp>, <&right_pinky_tap>;
  };
  #define RightPinkyMiddy right_pinky_middy_bilateral RIGHT_MIDDY_MOD RIGHT_MIDDY_KEY
  #ifndef RIGHT_RINGY_MIDDY_HOLDING_TYPE
  #define RIGHT_RINGY_MIDDY_HOLDING_TYPE RIGHT_RINGY_CHORD_HOLDING_TYPE
  #endif
  #ifndef RIGHT_RINGY_MIDDY_HOLDING_TIME
  #define RIGHT_RINGY_MIDDY_HOLDING_TIME RIGHT_RINGY_CHORD_HOLDING_TIME
  #endif
  #ifndef RIGHT_RINGY_MIDDY_STREAK_DECAY
  #define RIGHT_RINGY_MIDDY_STREAK_DECAY RIGHT_RINGY_CHORD_STREAK_DECAY
  #endif
  #ifndef RIGHT_RINGY_MIDDY_REPEAT_DECAY
  #define RIGHT_RINGY_MIDDY_REPEAT_DECAY RIGHT_RINGY_CHORD_REPEAT_DECAY
  #endif
  right_ringy_middy: homey_right_ringy_middy {
    compatible = "zmk,behavior-hold-tap";
    flavor = RIGHT_RINGY_HOLDING_TYPE;
    hold-trigger-key-positions = <LEFT_HAND_KEYS THUMB_KEYS>;
    hold-trigger-on-release; // wait for other home row mods
    tapping-term-ms = <RIGHT_RINGY_HOLDING_TIME>;
    quick-tap-ms = <RIGHT_RINGY_REPEAT_DECAY>;
    require-prior-idle-ms = <RIGHT_RINGY_STREAK_DECAY>;
    #binding-cells = <2>;
    bindings = <&kp>, <&kp>;
  };
  right_ringy_middy_bilateral: homey_right_ringy_middy_bilateral {
    compatible = "zmk,behavior-hold-tap";
    flavor = RIGHT_RINGY_HOLDING_TYPE;
    hold-trigger-key-positions = <LEFT_HAND_KEYS THUMB_KEYS>;
    hold-trigger-on-release; // wait for other home row mods
    tapping-term-ms = <RIGHT_RINGY_HOLDING_TIME>;
    quick-tap-ms = <RIGHT_RINGY_REPEAT_DECAY>;
    require-prior-idle-ms = <RIGHT_RINGY_STREAK_DECAY>;
    #binding-cells = <2>;
    bindings = <&kp>, <&right_ringy_tap>;
  };
  #define RightRingyMiddy right_ringy_middy_bilateral RIGHT_MIDDY_MOD RIGHT_MIDDY_KEY
  #ifndef RIGHT_INDEX_MIDDY_HOLDING_TYPE
  #define RIGHT_INDEX_MIDDY_HOLDING_TYPE RIGHT_INDEX_CHORD_HOLDING_TYPE
  #endif
  #ifndef RIGHT_INDEX_MIDDY_HOLDING_TIME
  #define RIGHT_INDEX_MIDDY_HOLDING_TIME RIGHT_INDEX_CHORD_HOLDING_TIME
  #endif
  #ifndef RIGHT_INDEX_MIDDY_STREAK_DECAY
  #define RIGHT_INDEX_MIDDY_STREAK_DECAY RIGHT_INDEX_CHORD_STREAK_DECAY
  #endif
  #ifndef RIGHT_INDEX_MIDDY_REPEAT_DECAY
  #define RIGHT_INDEX_MIDDY_REPEAT_DECAY RIGHT_INDEX_CHORD_REPEAT_DECAY
  #endif
  right_index_middy: homey_right_index_middy {
    compatible = "zmk,behavior-hold-tap";
    flavor = RIGHT_INDEX_HOLDING_TYPE;
    hold-trigger-key-positions = <LEFT_HAND_KEYS THUMB_KEYS>;
    hold-trigger-on-release; // wait for other home row mods
    tapping-term-ms = <RIGHT_INDEX_HOLDING_TIME>;
    quick-tap-ms = <RIGHT_INDEX_REPEAT_DECAY>;
    require-prior-idle-ms = <RIGHT_INDEX_STREAK_DECAY>;
    #binding-cells = <2>;
    bindings = <&kp>, <&kp>;
  };
  right_index_middy_bilateral: homey_right_index_middy_bilateral {
    compatible = "zmk,behavior-hold-tap";
    flavor = RIGHT_INDEX_HOLDING_TYPE;
    hold-trigger-key-positions = <LEFT_HAND_KEYS THUMB_KEYS>;
    hold-trigger-on-release; // wait for other home row mods
    tapping-term-ms = <RIGHT_INDEX_HOLDING_TIME>;
    quick-tap-ms = <RIGHT_INDEX_REPEAT_DECAY>;
    require-prior-idle-ms = <RIGHT_INDEX_STREAK_DECAY>;
    #binding-cells = <2>;
    bindings = <&kp>, <&right_index_tap>;
  };
  #define RightIndexMiddy right_index_middy_bilateral RIGHT_MIDDY_MOD RIGHT_MIDDY_KEY
  #ifndef LEFT_PINKY_INDEX_HOLDING_TYPE
  #define LEFT_PINKY_INDEX_HOLDING_TYPE LEFT_PINKY_CHORD_HOLDING_TYPE
  #endif
  #ifndef LEFT_PINKY_INDEX_HOLDING_TIME
  #define LEFT_PINKY_INDEX_HOLDING_TIME LEFT_PINKY_CHORD_HOLDING_TIME
  #endif
  #ifndef LEFT_PINKY_INDEX_STREAK_DECAY
  #define LEFT_PINKY_INDEX_STREAK_DECAY LEFT_PINKY_CHORD_STREAK_DECAY
  #endif
  #ifndef LEFT_PINKY_INDEX_REPEAT_DECAY
  #define LEFT_PINKY_INDEX_REPEAT_DECAY LEFT_PINKY_CHORD_REPEAT_DECAY
  #endif
  left_pinky_index: homey_left_pinky_index {
    compatible = "zmk,behavior-hold-tap";
    flavor = LEFT_PINKY_HOLDING_TYPE;
    hold-trigger-key-positions = <RIGHT_HAND_KEYS THUMB_KEYS>;
    hold-trigger-on-release; // wait for other home row mods
    tapping-term-ms = <LEFT_PINKY_HOLDING_TIME>;
    quick-tap-ms = <LEFT_PINKY_REPEAT_DECAY>;
    require-prior-idle-ms = <LEFT_PINKY_STREAK_DECAY>;
    #binding-cells = <2>;
    bindings = <&kp>, <&kp>;
  };
  left_pinky_index_bilateral: homey_left_pinky_index_bilateral {
    compatible = "zmk,behavior-hold-tap";
    flavor = LEFT_PINKY_HOLDING_TYPE;
    hold-trigger-key-positions = <RIGHT_HAND_KEYS THUMB_KEYS>;
    hold-trigger-on-release; // wait for other home row mods
    tapping-term-ms = <LEFT_PINKY_HOLDING_TIME>;
    quick-tap-ms = <LEFT_PINKY_REPEAT_DECAY>;
    require-prior-idle-ms = <LEFT_PINKY_STREAK_DECAY>;
    #binding-cells = <2>;
    bindings = <&kp>, <&left_pinky_tap>;
  };
  #define LeftPinkyIndex left_pinky_index_bilateral LEFT_INDEX_MOD LEFT_INDEX_KEY
  #ifndef LEFT_RINGY_INDEX_HOLDING_TYPE
  #define LEFT_RINGY_INDEX_HOLDING_TYPE LEFT_RINGY_CHORD_HOLDING_TYPE
  #endif
  #ifndef LEFT_RINGY_INDEX_HOLDING_TIME
  #define LEFT_RINGY_INDEX_HOLDING_TIME LEFT_RINGY_CHORD_HOLDING_TIME
  #endif
  #ifndef LEFT_RINGY_INDEX_STREAK_DECAY
  #define LEFT_RINGY_INDEX_STREAK_DECAY LEFT_RINGY_CHORD_STREAK_DECAY
  #endif
  #ifndef LEFT_RINGY_INDEX_REPEAT_DECAY
  #define LEFT_RINGY_INDEX_REPEAT_DECAY LEFT_RINGY_CHORD_REPEAT_DECAY
  #endif
  left_ringy_index: homey_left_ringy_index {
    compatible = "zmk,behavior-hold-tap";
    flavor = LEFT_RINGY_HOLDING_TYPE;
    hold-trigger-key-positions = <RIGHT_HAND_KEYS THUMB_KEYS>;
    hold-trigger-on-release; // wait for other home row mods
    tapping-term-ms = <LEFT_RINGY_HOLDING_TIME>;
    quick-tap-ms = <LEFT_RINGY_REPEAT_DECAY>;
    require-prior-idle-ms = <LEFT_RINGY_STREAK_DECAY>;
    #binding-cells = <2>;
    bindings = <&kp>, <&kp>;
  };
  left_ringy_index_bilateral: homey_left_ringy_index_bilateral {
    compatible = "zmk,behavior-hold-tap";
    flavor = LEFT_RINGY_HOLDING_TYPE;
    hold-trigger-key-positions = <RIGHT_HAND_KEYS THUMB_KEYS>;
    hold-trigger-on-release; // wait for other home row mods
    tapping-term-ms = <LEFT_RINGY_HOLDING_TIME>;
    quick-tap-ms = <LEFT_RINGY_REPEAT_DECAY>;
    require-prior-idle-ms = <LEFT_RINGY_STREAK_DECAY>;
    #binding-cells = <2>;
    bindings = <&kp>, <&left_ringy_tap>;
  };
  #define LeftRingyIndex left_ringy_index_bilateral LEFT_INDEX_MOD LEFT_INDEX_KEY
  #ifndef LEFT_MIDDY_INDEX_HOLDING_TYPE
  #define LEFT_MIDDY_INDEX_HOLDING_TYPE LEFT_MIDDY_CHORD_HOLDING_TYPE
  #endif
  #ifndef LEFT_MIDDY_INDEX_HOLDING_TIME
  #define LEFT_MIDDY_INDEX_HOLDING_TIME LEFT_MIDDY_CHORD_HOLDING_TIME
  #endif
  #ifndef LEFT_MIDDY_INDEX_STREAK_DECAY
  #define LEFT_MIDDY_INDEX_STREAK_DECAY LEFT_MIDDY_CHORD_STREAK_DECAY
  #endif
  #ifndef LEFT_MIDDY_INDEX_REPEAT_DECAY
  #define LEFT_MIDDY_INDEX_REPEAT_DECAY LEFT_MIDDY_CHORD_REPEAT_DECAY
  #endif
  left_middy_index: homey_left_middy_index {
    compatible = "zmk,behavior-hold-tap";
    flavor = LEFT_MIDDY_HOLDING_TYPE;
    hold-trigger-key-positions = <RIGHT_HAND_KEYS THUMB_KEYS>;
    hold-trigger-on-release; // wait for other home row mods
    tapping-term-ms = <LEFT_MIDDY_HOLDING_TIME>;
    quick-tap-ms = <LEFT_MIDDY_REPEAT_DECAY>;
    require-prior-idle-ms = <LEFT_MIDDY_STREAK_DECAY>;
    #binding-cells = <2>;
    bindings = <&kp>, <&kp>;
  };
  left_middy_index_bilateral: homey_left_middy_index_bilateral {
    compatible = "zmk,behavior-hold-tap";
    flavor = LEFT_MIDDY_HOLDING_TYPE;
    hold-trigger-key-positions = <RIGHT_HAND_KEYS THUMB_KEYS>;
    hold-trigger-on-release; // wait for other home row mods
    tapping-term-ms = <LEFT_MIDDY_HOLDING_TIME>;
    quick-tap-ms = <LEFT_MIDDY_REPEAT_DECAY>;
    require-prior-idle-ms = <LEFT_MIDDY_STREAK_DECAY>;
    #binding-cells = <2>;
    bindings = <&kp>, <&left_middy_tap>;
  };
  #define LeftMiddyIndex left_middy_index_bilateral LEFT_INDEX_MOD LEFT_INDEX_KEY
  #ifndef RIGHT_PINKY_INDEX_HOLDING_TYPE
  #define RIGHT_PINKY_INDEX_HOLDING_TYPE RIGHT_PINKY_CHORD_HOLDING_TYPE
  #endif
  #ifndef RIGHT_PINKY_INDEX_HOLDING_TIME
  #define RIGHT_PINKY_INDEX_HOLDING_TIME RIGHT_PINKY_CHORD_HOLDING_TIME
  #endif
  #ifndef RIGHT_PINKY_INDEX_STREAK_DECAY
  #define RIGHT_PINKY_INDEX_STREAK_DECAY RIGHT_PINKY_CHORD_STREAK_DECAY
  #endif
  #ifndef RIGHT_PINKY_INDEX_REPEAT_DECAY
  #define RIGHT_PINKY_INDEX_REPEAT_DECAY RIGHT_PINKY_CHORD_REPEAT_DECAY
  #endif
  right_pinky_index: homey_right_pinky_index {
    compatible = "zmk,behavior-hold-tap";
    flavor = RIGHT_PINKY_HOLDING_TYPE;
    hold-trigger-key-positions = <LEFT_HAND_KEYS THUMB_KEYS>;
    hold-trigger-on-release; // wait for other home row mods
    tapping-term-ms = <RIGHT_PINKY_HOLDING_TIME>;
    quick-tap-ms = <RIGHT_PINKY_REPEAT_DECAY>;
    require-prior-idle-ms = <RIGHT_PINKY_STREAK_DECAY>;
    #binding-cells = <2>;
    bindings = <&kp>, <&kp>;
  };
  right_pinky_index_bilateral: homey_right_pinky_index_bilateral {
    compatible = "zmk,behavior-hold-tap";
    flavor = RIGHT_PINKY_HOLDING_TYPE;
    hold-trigger-key-positions = <LEFT_HAND_KEYS THUMB_KEYS>;
    hold-trigger-on-release; // wait for other home row mods
    tapping-term-ms = <RIGHT_PINKY_HOLDING_TIME>;
    quick-tap-ms = <RIGHT_PINKY_REPEAT_DECAY>;
    require-prior-idle-ms = <RIGHT_PINKY_STREAK_DECAY>;
    #binding-cells = <2>;
    bindings = <&kp>, <&right_pinky_tap>;
  };
  #define RightPinkyIndex right_pinky_index_bilateral RIGHT_INDEX_MOD RIGHT_INDEX_KEY
  #ifndef RIGHT_RINGY_INDEX_HOLDING_TYPE
  #define RIGHT_RINGY_INDEX_HOLDING_TYPE RIGHT_RINGY_CHORD_HOLDING_TYPE
  #endif
  #ifndef RIGHT_RINGY_INDEX_HOLDING_TIME
  #define RIGHT_RINGY_INDEX_HOLDING_TIME RIGHT_RINGY_CHORD_HOLDING_TIME
  #endif
  #ifndef RIGHT_RINGY_INDEX_STREAK_DECAY
  #define RIGHT_RINGY_INDEX_STREAK_DECAY RIGHT_RINGY_CHORD_STREAK_DECAY
  #endif
  #ifndef RIGHT_RINGY_INDEX_REPEAT_DECAY
  #define RIGHT_RINGY_INDEX_REPEAT_DECAY RIGHT_RINGY_CHORD_REPEAT_DECAY
  #endif
  right_ringy_index: homey_right_ringy_index {
    compatible = "zmk,behavior-hold-tap";
    flavor = RIGHT_RINGY_HOLDING_TYPE;
    hold-trigger-key-positions = <LEFT_HAND_KEYS THUMB_KEYS>;
    hold-trigger-on-release; // wait for other home row mods
    tapping-term-ms = <RIGHT_RINGY_HOLDING_TIME>;
    quick-tap-ms = <RIGHT_RINGY_REPEAT_DECAY>;
    require-prior-idle-ms = <RIGHT_RINGY_STREAK_DECAY>;
    #binding-cells = <2>;
    bindings = <&kp>, <&kp>;
  };
  right_ringy_index_bilateral: homey_right_ringy_index_bilateral {
    compatible = "zmk,behavior-hold-tap";
    flavor = RIGHT_RINGY_HOLDING_TYPE;
    hold-trigger-key-positions = <LEFT_HAND_KEYS THUMB_KEYS>;
    hold-trigger-on-release; // wait for other home row mods
    tapping-term-ms = <RIGHT_RINGY_HOLDING_TIME>;
    quick-tap-ms = <RIGHT_RINGY_REPEAT_DECAY>;
    require-prior-idle-ms = <RIGHT_RINGY_STREAK_DECAY>;
    #binding-cells = <2>;
    bindings = <&kp>, <&right_ringy_tap>;
  };
  #define RightRingyIndex right_ringy_index_bilateral RIGHT_INDEX_MOD RIGHT_INDEX_KEY
  #ifndef RIGHT_MIDDY_INDEX_HOLDING_TYPE
  #define RIGHT_MIDDY_INDEX_HOLDING_TYPE RIGHT_MIDDY_CHORD_HOLDING_TYPE
  #endif
  #ifndef RIGHT_MIDDY_INDEX_HOLDING_TIME
  #define RIGHT_MIDDY_INDEX_HOLDING_TIME RIGHT_MIDDY_CHORD_HOLDING_TIME
  #endif
  #ifndef RIGHT_MIDDY_INDEX_STREAK_DECAY
  #define RIGHT_MIDDY_INDEX_STREAK_DECAY RIGHT_MIDDY_CHORD_STREAK_DECAY
  #endif
  #ifndef RIGHT_MIDDY_INDEX_REPEAT_DECAY
  #define RIGHT_MIDDY_INDEX_REPEAT_DECAY RIGHT_MIDDY_CHORD_REPEAT_DECAY
  #endif
  right_middy_index: homey_right_middy_index {
    compatible = "zmk,behavior-hold-tap";
    flavor = RIGHT_MIDDY_HOLDING_TYPE;
    hold-trigger-key-positions = <LEFT_HAND_KEYS THUMB_KEYS>;
    hold-trigger-on-release; // wait for other home row mods
    tapping-term-ms = <RIGHT_MIDDY_HOLDING_TIME>;
    quick-tap-ms = <RIGHT_MIDDY_REPEAT_DECAY>;
    require-prior-idle-ms = <RIGHT_MIDDY_STREAK_DECAY>;
    #binding-cells = <2>;
    bindings = <&kp>, <&kp>;
  };
  right_middy_index_bilateral: homey_right_middy_index_bilateral {
    compatible = "zmk,behavior-hold-tap";
    flavor = RIGHT_MIDDY_HOLDING_TYPE;
    hold-trigger-key-positions = <LEFT_HAND_KEYS THUMB_KEYS>;
    hold-trigger-on-release; // wait for other home row mods
    tapping-term-ms = <RIGHT_MIDDY_HOLDING_TIME>;
    quick-tap-ms = <RIGHT_MIDDY_REPEAT_DECAY>;
    require-prior-idle-ms = <RIGHT_MIDDY_STREAK_DECAY>;
    #binding-cells = <2>;
    bindings = <&kp>, <&right_middy_tap>;
  };
  #define RightMiddyIndex right_middy_index_bilateral RIGHT_INDEX_MOD RIGHT_INDEX_KEY

  //
  // Thumb cluster hold-tap keys for Miryoku layers
  //
  thumb: thumb_layer_access {
    compatible = "zmk,behavior-hold-tap";
    flavor = THUMB_HOLDING_TYPE;
    tapping-term-ms = <THUMB_HOLDING_TIME>;
    quick-tap-ms = <THUMB_REPEAT_DECAY>; // enable repeat
    #binding-cells = <2>;
    bindings = <&mo>, <&kp>;
  };
  space: thumb_layer_access_spacebar {
    compatible = "zmk,behavior-hold-tap";
    flavor = SPACE_HOLDING_TYPE;
    tapping-term-ms = <SPACE_HOLDING_TIME>;
    quick-tap-ms = <SPACE_REPEAT_DECAY>; // enable repeat
    #binding-cells = <2>;
    bindings = <&mo>, <&kp>;
    #ifdef SPACE_FORGIVENESS
    retro-tap; // tap on standalone hold
    #endif
  };

  //
  // RGB with mods
  //
  rgb_effect: rgb_effect {
    compatible = "zmk,behavior-mod-morph";
    #binding-cells = <0>;
    bindings = <&rgb_ug RGB_EFF>, <&rgb_ug RGB_EFR>;
    mods = <(MOD_LSFT|MOD_RSFT)>;
  };
  rgb_hue: rgb_hue {
    compatible = "zmk,behavior-mod-morph";
    #binding-cells = <0>;
    bindings = <&rgb_ug RGB_HUI>, <&rgb_ug RGB_HUD>;
    mods = <(MOD_LSFT|MOD_RSFT)>;
  };
  rgb_saturation: rgb_saturation {
    compatible = "zmk,behavior-mod-morph";
    #binding-cells = <0>;
    bindings = <&rgb_ug RGB_SAI>, <&rgb_ug RGB_SAD>;
    mods = <(MOD_LSFT|MOD_RSFT)>;
  };
  rgb_brightness: rgb_brightness {
    compatible = "zmk,behavior-mod-morph";
    #binding-cells = <0>;
    bindings = <&rgb_ug RGB_BRI>, <&rgb_ug RGB_BRD>;
    mods = <(MOD_LSFT|MOD_RSFT)>;
  };
  rgb_speed: rgb_speed {
    compatible = "zmk,behavior-mod-morph";
    #binding-cells = <0>;
    bindings = <&rgb_ug RGB_SPD>, <&rgb_ug RGB_SPI>;
    mods = <(MOD_LSFT|MOD_RSFT)>;
  };

  //////////////////////////////////////////////////////////////////////////
  //
  // ZMK global overrides
  //
  //////////////////////////////////////////////////////////////////////////

  //
  // CapsWord - ported from Pascal Getreuer's extension for QMK
  // - https://zmk.dev/docs/behaviors/caps-word
  // - https://getreuer.info/posts/keyboards/caps-word/index.html
  //
  behavior_caps_word {
    continue-list = <
      UNDERSCORE MINUS
      BACKSPACE DELETE
      N1 N2 N3 N4 N5 N6 N7 N8 N9 N0
    >;
  };

};

macros {
  #define select_all kp _C(A)
  #define select_all_mac kp _C_Mac(A)
};
/*HACK*/};

/*HACK*//{

//////////////////////////////////////////////////////////////////////////
//
// Mouse keys (keyboard mouse control) requires v24.12 firmware or newer:
// override the "HID_POINTING" setting to "y" in Advanced Configuration
// and then select "v24.12" firmware from the drop-down menu located at
// Glove80 Layout Editor > Settings > Advanced Settings > Firmware Version
//
// Alternatively, you can use either PR36 or PR23 beta firmware for this:
// select "community.pr36.mouse-keys" from the drop-down menu located at
// Glove80 Layout Editor > Settings > Advanced Settings > Firmware Version
//
// - https://github.com/moergo-sc/zmk/pull/36
// - https://github.com/moergo-sc/zmk/pull/23
// - https://gist.github.com/krissen/dd27082e7ab0575619c7a31f4d2ec7ae
// - https://github.com/zmkfirmware/zmk/compare/main...urob:zmk:mouse-3.2
// - https://github.com/caksoylar/zmk-config/commit/0020c23c544cd7111013f0114609d1fb90e0e475
// - https://github.com/caksoylar/zmk-config/commit/e35ee2f08788927683df7bbdd7fc73434473886e
//
//////////////////////////////////////////////////////////////////////////

//
// NATURAL_SCROLLING reverses the directionality of the mouse scroll wheel
// to support "natural scrolling" in macOS and other desktop environments.
//
//#define NATURAL_SCROLLING

#define MOUSE_SCROLL_UP    SCRL_UP
#define MOUSE_SCROLL_DOWN  SCRL_DOWN
#define MOUSE_SCROLL_LEFT  SCRL_LEFT
#define MOUSE_SCROLL_RIGHT SCRL_RIGHT

//
// MOUSE_MOTION_DELAY defines how long to wait (milliseconds) before starting
// to move the mouse pointer.
//
#ifndef MOUSE_MOTION_DELAY
#define MOUSE_MOTION_DELAY 0
#endif

//
// MOUSE_MOTION_ACCELERATION_EXPONENT sets how the mouse pointer accelerates:
//
// acceleration exponent 0: uniform speed
// acceleration exponent 1: uniform acceleration
// acceleration exponent 2: uniform jerk
//
#ifndef MOUSE_MOTION_ACCELERATION_EXPONENT
#define MOUSE_MOTION_ACCELERATION_EXPONENT 1
#endif

//
// MOUSE_MOTION_TIME_TO_MAXIMUM_SPEED defines how long to wait (milliseconds)
// before the mouse pointer speed is suddenly boosted to the maximum value.
//
#ifndef MOUSE_MOTION_TIME_TO_MAXIMUM_SPEED
#define MOUSE_MOTION_TIME_TO_MAXIMUM_SPEED 300
#endif

//
// MOUSE_MOTION_MAXIMUM_SPEED defines how quickly the mouse pointer can move.
//
#ifndef MOUSE_MOTION_MAXIMUM_SPEED
#define MOUSE_MOTION_MAXIMUM_SPEED 600
#endif

//
// MOUSE_SCROLL_DELAY defines how long to wait (milliseconds) before starting
// to move the mouse pointer.
//
#ifndef MOUSE_SCROLL_DELAY
#define MOUSE_SCROLL_DELAY 0
#endif

//
// MOUSE_SCROLL_ACCELERATION_EXPONENT sets how the mouse pointer accelerates:
//
// acceleration exponent 0: uniform speed
// acceleration exponent 1: uniform acceleration
// acceleration exponent 2: uniform jerk
//
#ifndef MOUSE_SCROLL_ACCELERATION_EXPONENT
#define MOUSE_SCROLL_ACCELERATION_EXPONENT 0
#endif

//
// MOUSE_SCROLL_TIME_TO_MAXIMUM_SPEED defines how long to wait (milliseconds)
// before the mouse pointer speed is suddenly boosted to the maximum value.
//
#ifndef MOUSE_SCROLL_TIME_TO_MAXIMUM_SPEED
#define MOUSE_SCROLL_TIME_TO_MAXIMUM_SPEED 300
#endif

//
// MOUSE_SCROLL_MAXIMUM_SPEED defines how quickly the mouse wheel can scroll.
//
#ifndef MOUSE_SCROLL_MAXIMUM_SPEED
#define MOUSE_SCROLL_MAXIMUM_SPEED 10
#endif

/*HACK*/};

// ==== MOUSE-KEY <section begins> ====
#define ZMK_POINTING_DEFAULT_MOVE_VAL MOUSE_MOTION_MAXIMUM_SPEED
#define ZMK_POINTING_DEFAULT_SCRL_VAL MOUSE_SCROLL_MAXIMUM_SPEED
#include <dt-bindings/zmk/pointing.h>
&mmv {
  delay-ms = <MOUSE_MOTION_DELAY>;
  acceleration-exponent = <MOUSE_MOTION_ACCELERATION_EXPONENT>;
  time-to-max-speed-ms = <MOUSE_MOTION_TIME_TO_MAXIMUM_SPEED>;
};
&msc {
  delay-ms = <MOUSE_SCROLL_DELAY>;
  acceleration-exponent = <MOUSE_SCROLL_ACCELERATION_EXPONENT>;
  time-to-max-speed-ms = <MOUSE_SCROLL_TIME_TO_MAXIMUM_SPEED>;
};
//
// Scaling for mouse scrolling, based on @caksoylar's example:
// https://github.com/caksoylar/zmk-config/commit/e35ee2f08788927683df7bbdd7fc73434473886e
//
#include <zephyr/dt-bindings/input/input-event-codes.h>
/ {
  input_processors {
    zip_scroll_scaler: zip_scroll_scaler {
      compatible = "zmk,input-processor-scaler";
      #input-processor-cells = <2>;
      type = <INPUT_EV_REL>;
      codes = <INPUT_REL_WHEEL INPUT_REL_HWHEEL>;
      track-remainders;
    };
  };
};
// ==== MOUSE-KEY <section ends> =====

/* Automatically generated keymap */
/ {
    keymap {
        compatible = "zmk,keymap";


        layer_QWERTY_Mac {
            bindings = <
                            &kp Q                             &kp W                             &kp E                             &kp R                   &kp T                      &kp Y                              &kp U                              &kp I                              &kp O                                 &kp P
 &LeftPinky (A, LAYER_QWERTY_Mac)  &LeftRingy (S, LAYER_QWERTY_Mac)  &LeftMiddy (D, LAYER_QWERTY_Mac)  &LeftIndex (F, LAYER_QWERTY_Mac)                   &kp G                      &kp H  &RightIndex (J, LAYER_QWERTY_Mac)  &RightMiddy (K, LAYER_QWERTY_Mac)  &RightRingy (L, LAYER_QWERTY_Mac)  &RightPinky (SEMI, LAYER_QWERTY_Mac)
        &thumb LAYER_Button_Mac Z                             &kp X                             &kp C                             &kp V                   &kp B                      &kp N                              &kp M                          &kp COMMA                            &kp DOT          &thumb LAYER_Button_Mac FSLH
                                                                              &thumb LAYER_System ESC         &space LAYER_Cursor SPACE  &thumb LAYER_Mouse TAB  &thumb LAYER_Symbol ENTER      &thumb LAYER_Number BACKSPACE       &thumb LAYER_Function DELETE
            >;
        };

        layer_QWERTY {
            bindings = <
                        &kp Q                         &kp W                         &kp E                         &kp R                   &kp T                      &kp Y                          &kp U                          &kp I                          &kp O                             &kp P
 &LeftPinky (A, LAYER_QWERTY)  &LeftRingy (S, LAYER_QWERTY)  &LeftMiddy (D, LAYER_QWERTY)  &LeftIndex (F, LAYER_QWERTY)                   &kp G                      &kp H  &RightIndex (J, LAYER_QWERTY)  &RightMiddy (K, LAYER_QWERTY)  &RightRingy (L, LAYER_QWERTY)  &RightPinky (SEMI, LAYER_QWERTY)
        &thumb LAYER_Button Z                         &kp X                         &kp C                         &kp V                   &kp B                      &kp N                          &kp M                      &kp COMMA                        &kp DOT          &thumb LAYER_Button FSLH
                                                                  &thumb LAYER_System ESC     &space LAYER_Cursor SPACE  &thumb LAYER_Mouse TAB  &thumb LAYER_Symbol ENTER  &thumb LAYER_Number BACKSPACE   &thumb LAYER_Function DELETE
            >;
        };

        layer_Typing {
            bindings = <
             &trans              &trans              &trans              &trans         &trans         &trans               &trans               &trans               &trans               &trans
 &kp LEFT_PINKY_KEY  &kp LEFT_RINGY_KEY  &kp LEFT_MIDDY_KEY  &kp LEFT_INDEX_KEY         &trans         &trans  &kp RIGHT_INDEX_KEY  &kp RIGHT_MIDDY_KEY  &kp RIGHT_RINGY_KEY  &kp RIGHT_PINKY_KEY
    &kp KEY_LH_C5R3              &trans              &trans              &trans         &trans         &trans               &trans               &trans               &trans      &kp KEY_RH_C5R3
                                              &kp KEY_LH_T1       &kp KEY_LH_T2  &kp KEY_LH_T3  &kp KEY_RH_T3               &trans        &kp KEY_RH_T1
            >;
        };

        layer_LeftPinky {
            bindings = <
 &left_pinky_tap KEY_LH_C5R1  &left_pinky_tap KEY_LH_C4R1  &left_pinky_tap KEY_LH_C3R1  &left_pinky_tap KEY_LH_C2R1  &left_pinky_tap KEY_LH_C1R1  &trans               &trans               &trans               &trans               &trans
                       &none              &LeftPinkyRingy              &LeftPinkyMiddy              &LeftPinkyIndex  &left_pinky_tap KEY_LH_C1R2  &trans  &kp RIGHT_INDEX_KEY  &kp RIGHT_MIDDY_KEY  &kp RIGHT_RINGY_KEY  &kp RIGHT_PINKY_KEY
 &left_pinky_tap KEY_LH_C5R3  &left_pinky_tap KEY_LH_C4R3  &left_pinky_tap KEY_LH_C3R3  &left_pinky_tap KEY_LH_C2R3  &left_pinky_tap KEY_LH_C1R3  &trans               &trans               &trans               &trans               &trans
                                                                                &trans                       &trans                       &trans  &trans               &trans               &trans
            >;
        };

        layer_LeftRingy {
            bindings = <
 &left_ringy_tap KEY_LH_C5R1  &left_ringy_tap KEY_LH_C4R1  &left_ringy_tap KEY_LH_C3R1  &left_ringy_tap KEY_LH_C2R1  &left_ringy_tap KEY_LH_C1R1  &trans               &trans               &trans               &trans               &trans
             &LeftRingyPinky                        &none              &LeftRingyMiddy              &LeftRingyIndex  &left_ringy_tap KEY_LH_C1R2  &trans  &kp RIGHT_INDEX_KEY  &kp RIGHT_MIDDY_KEY  &kp RIGHT_RINGY_KEY  &kp RIGHT_PINKY_KEY
 &left_ringy_tap KEY_LH_C5R3  &left_ringy_tap KEY_LH_C4R3  &left_ringy_tap KEY_LH_C3R3  &left_ringy_tap KEY_LH_C2R3  &left_ringy_tap KEY_LH_C1R3  &trans               &trans               &trans               &trans               &trans
                                                                                &trans                       &trans                       &trans  &trans               &trans               &trans
            >;
        };

        layer_LeftMiddy {
            bindings = <
 &left_middy_tap KEY_LH_C5R1  &left_middy_tap KEY_LH_C4R1  &left_middy_tap KEY_LH_C3R1  &left_middy_tap KEY_LH_C2R1  &left_middy_tap KEY_LH_C1R1  &trans               &trans               &trans               &trans               &trans
             &LeftMiddyPinky              &LeftMiddyRingy                        &none              &LeftMiddyIndex  &left_middy_tap KEY_LH_C1R2  &trans  &kp RIGHT_INDEX_KEY  &kp RIGHT_MIDDY_KEY  &kp RIGHT_RINGY_KEY  &kp RIGHT_PINKY_KEY
 &left_middy_tap KEY_LH_C5R3  &left_middy_tap KEY_LH_C4R3  &left_middy_tap KEY_LH_C3R3  &left_middy_tap KEY_LH_C2R3  &left_middy_tap KEY_LH_C1R3  &trans               &trans               &trans               &trans               &trans
                                                                                &trans                       &trans                       &trans  &trans               &trans               &trans
            >;
        };

        layer_LeftIndex {
            bindings = <
 &left_index_tap KEY_LH_C5R1  &left_index_tap KEY_LH_C4R1  &left_index_tap KEY_LH_C3R1  &left_index_tap KEY_LH_C2R1  &left_index_tap KEY_LH_C1R1  &trans               &trans               &trans               &trans               &trans
             &LeftIndexPinky              &LeftIndexRingy              &LeftIndexMiddy                        &none  &left_index_tap KEY_LH_C1R2  &trans  &kp RIGHT_INDEX_KEY  &kp RIGHT_MIDDY_KEY  &kp RIGHT_RINGY_KEY  &kp RIGHT_PINKY_KEY
 &left_index_tap KEY_LH_C5R3  &left_index_tap KEY_LH_C4R3  &left_index_tap KEY_LH_C3R3  &left_index_tap KEY_LH_C2R3  &left_index_tap KEY_LH_C1R3  &trans               &trans               &trans               &trans               &trans
                                                                                &trans                       &trans                       &trans  &trans               &trans               &trans
            >;
        };

        layer_RightPinky {
            bindings = <
             &trans              &trans              &trans              &trans  &trans  &right_pinky_tap KEY_RH_C1R1  &right_pinky_tap KEY_RH_C2R1  &right_pinky_tap KEY_RH_C3R1  &right_pinky_tap KEY_RH_C4R1  &right_pinky_tap KEY_RH_C5R1
 &kp LEFT_PINKY_KEY  &kp LEFT_RINGY_KEY  &kp LEFT_MIDDY_KEY  &kp LEFT_INDEX_KEY  &trans  &right_pinky_tap KEY_RH_C1R2              &RightPinkyIndex              &RightPinkyMiddy              &RightPinkyRingy                         &none
             &trans              &trans              &trans              &trans  &trans  &right_pinky_tap KEY_RH_C1R3  &right_pinky_tap KEY_RH_C2R3  &right_pinky_tap KEY_RH_C3R3  &right_pinky_tap KEY_RH_C4R3  &right_pinky_tap KEY_RH_C5R3
                                                     &trans              &trans  &trans                        &trans                        &trans                        &trans
            >;
        };

        layer_RightRingy {
            bindings = <
             &trans              &trans              &trans              &trans  &trans  &right_ringy_tap KEY_RH_C1R1  &right_ringy_tap KEY_RH_C2R1  &right_ringy_tap KEY_RH_C3R1  &right_ringy_tap KEY_RH_C4R1  &right_ringy_tap KEY_RH_C5R1
 &kp LEFT_PINKY_KEY  &kp LEFT_RINGY_KEY  &kp LEFT_MIDDY_KEY  &kp LEFT_INDEX_KEY  &trans  &right_ringy_tap KEY_RH_C1R2              &RightRingyIndex              &RightRingyMiddy                         &none              &RightRingyPinky
             &trans              &trans              &trans              &trans  &trans  &right_ringy_tap KEY_RH_C1R3  &right_ringy_tap KEY_RH_C2R3  &right_ringy_tap KEY_RH_C3R3  &right_ringy_tap KEY_RH_C4R3  &right_ringy_tap KEY_RH_C5R3
                                                     &trans              &trans  &trans                        &trans                        &trans                        &trans
            >;
        };

        layer_RightMiddy {
            bindings = <
             &trans              &trans              &trans              &trans  &trans  &right_middy_tap KEY_RH_C1R1  &right_middy_tap KEY_RH_C2R1  &right_middy_tap KEY_RH_C3R1  &right_middy_tap KEY_RH_C4R1  &right_middy_tap KEY_RH_C5R1
 &kp LEFT_PINKY_KEY  &kp LEFT_RINGY_KEY  &kp LEFT_MIDDY_KEY  &kp LEFT_INDEX_KEY  &trans  &right_middy_tap KEY_RH_C1R2              &RightMiddyIndex                         &none              &RightMiddyRingy              &RightMiddyPinky
             &trans              &trans              &trans              &trans  &trans  &right_middy_tap KEY_RH_C1R3  &right_middy_tap KEY_RH_C2R3  &right_middy_tap KEY_RH_C3R3  &right_middy_tap KEY_RH_C4R3  &right_middy_tap KEY_RH_C5R3
                                                     &trans              &trans  &trans                        &trans                        &trans                        &trans
            >;
        };

        layer_RightIndex {
            bindings = <
             &trans              &trans              &trans              &trans  &trans  &right_index_tap KEY_RH_C1R1  &right_index_tap KEY_RH_C2R1  &right_index_tap KEY_RH_C3R1  &right_index_tap KEY_RH_C4R1  &right_index_tap KEY_RH_C5R1
 &kp LEFT_PINKY_KEY  &kp LEFT_RINGY_KEY  &kp LEFT_MIDDY_KEY  &kp LEFT_INDEX_KEY  &trans  &right_index_tap KEY_RH_C1R2                         &none              &RightIndexMiddy              &RightIndexRingy              &RightIndexPinky
             &trans              &trans              &trans              &trans  &trans  &right_index_tap KEY_RH_C1R3  &right_index_tap KEY_RH_C2R3  &right_index_tap KEY_RH_C3R3  &right_index_tap KEY_RH_C4R3  &right_index_tap KEY_RH_C5R3
                                                     &trans              &trans  &trans                        &trans                        &trans                        &trans
            >;
        };

        layer_System {
            bindings = <
        &bootloader   &tog LAYER_Typing                &to 1               &to 0  &studio_unlock  &rgb_effect      &rgb_hue  &rgb_saturation  &rgb_brightness  &rgb_ug RGB_TOG
 &kp LEFT_PINKY_MOD  &kp LEFT_RINGY_MOD   &kp LEFT_MIDDY_MOD  &kp LEFT_INDEX_MOD           &none   &kp C_PREV  &kp C_VOL_DN     &kp C_VOL_UP       &kp C_NEXT       &rgb_speed
     &kp LS(DELETE)          &kp DELETE  &tog LAYER_Function   &tog LAYER_System           &none   &bt BT_CLR         &bt_0            &bt_1            &bt_2            &bt_3
                                                       &none               &none           &none   &kp C_STOP      &kp C_PP       &kp C_MUTE
            >;
        };

        layer_Cursor {
            bindings = <
              &none   &tog LAYER_Typing               &none               &to 0  &none      &none       &none      &none      &none      &none
 &kp LEFT_PINKY_MOD  &kp LEFT_RINGY_MOD  &kp LEFT_MIDDY_MOD  &kp LEFT_INDEX_MOD  &none   &kp LEFT    &kp DOWN     &kp UP  &kp RIGHT   &kp CAPS
     &kp LS(DELETE)          &kp DELETE   &tog LAYER_Number   &tog LAYER_Cursor  &none   &kp HOME   &kp PG_DN  &kp PG_UP    &kp END    &kp INS
                                                      &none               &none  &none    &kp RET    &kp BSPC    &kp DEL
            >;
        };

        layer_Mouse {
            bindings = <
              &none   &tog LAYER_Typing               &none               &to 0  &none                   &none                   &none                 &none                    &none      &none
 &kp LEFT_PINKY_MOD  &kp LEFT_RINGY_MOD  &kp LEFT_MIDDY_MOD  &kp LEFT_INDEX_MOD  &none          &mmv MOVE_LEFT          &mmv MOVE_DOWN          &mmv MOVE_UP          &mmv MOVE_RIGHT   &mkp MB4
     &kp LS(DELETE)          &kp DELETE   &tog LAYER_Symbol    &tog LAYER_Mouse  &none  &msc MOUSE_SCROLL_LEFT  &msc MOUSE_SCROLL_DOWN  &msc MOUSE_SCROLL_UP  &msc MOUSE_SCROLL_RIGHT   &mkp MB5
                                                      &none               &none  &none               &mkp RCLK               &mkp LCLK             &mkp MCLK
            >;
        };

        layer_Symbol {
            bindings = <
  &kp LS(LBKT)  &kp LS(N7)    &kp LS(N8)  &kp LS(N9)   &kp LS(RBKT)  &none                &to 0                &none    &tog LAYER_Typing                &none
   &kp LS(SQT)  &kp LS(N4)    &kp LS(N5)  &kp LS(N6)  &kp LS(EQUAL)  &none  &kp RIGHT_INDEX_MOD  &kp RIGHT_MIDDY_MOD  &kp RIGHT_RINGY_MOD  &kp RIGHT_PINKY_MOD
 &kp LS(GRAVE)  &kp LS(N1)    &kp LS(N2)  &kp LS(N3)   &kp LS(BSLH)  &none    &tog LAYER_Symbol     &tog LAYER_Mouse           &kp DELETE       &kp LS(DELETE)
                            &kp LS(FSLH)  &kp LS(N0)  &kp LS(MINUS)  &none                &none                &none
            >;
        };

        layer_Number {
            bindings = <
  &kp LBKT  &kp N7    &kp N8  &kp N9   &kp RBKT  &none                &to 0                &none    &tog LAYER_Typing                &none
   &kp SQT  &kp N4    &kp N5  &kp N6  &kp EQUAL  &none  &kp RIGHT_INDEX_MOD  &kp RIGHT_MIDDY_MOD  &kp RIGHT_RINGY_MOD  &kp RIGHT_PINKY_MOD
 &kp GRAVE  &kp N1    &kp N2  &kp N3   &kp BSLH  &none    &tog LAYER_Number    &tog LAYER_Cursor           &kp DELETE       &kp LS(DELETE)
                    &kp FSLH  &kp N0  &kp MINUS  &none                &none                &none
            >;
        };

        layer_Function {
            bindings = <
 &kp F12  &kp F7     &kp F8     &kp F9        &kp PSCRN  &studio_unlock                &to 0                &to 1    &tog LAYER_Typing          &bootloader
 &kp F11  &kp F4     &kp F5     &kp F6         &kp SLCK           &none  &kp RIGHT_INDEX_MOD  &kp RIGHT_MIDDY_MOD  &kp RIGHT_RINGY_MOD  &kp RIGHT_PINKY_MOD
 &kp F10  &kp F1     &kp F2     &kp F3  &kp PAUSE_BREAK           &none  &tog LAYER_Function    &tog LAYER_System           &kp DELETE       &kp LS(DELETE)
                  &kp K_APP  &kp SPACE          &kp TAB           &none                &none                &none
            >;
        };

        layer_Button_Mac {
            bindings = <
              &none      &kp _PSCRN_Mac       &kp _FIND_Mac             &kp RET   &select_all_mac    &select_all_mac              &kp RET        &kp _FIND_Mac       &kp _PSCRN_Mac                &none
 &kp LEFT_PINKY_MOD  &kp LEFT_RINGY_MOD  &kp LEFT_MIDDY_MOD  &kp LEFT_INDEX_MOD     &kp _UNDO_Mac      &kp _UNDO_Mac  &kp RIGHT_INDEX_MOD  &kp RIGHT_MIDDY_MOD  &kp RIGHT_RINGY_MOD  &kp RIGHT_PINKY_MOD
      &kp _UNDO_Mac        &kp _CUT_Mac       &kp _COPY_Mac      &kp _PASTE_Mac     &kp _REDO_Mac      &kp _REDO_Mac       &kp _PASTE_Mac        &kp _COPY_Mac         &kp _CUT_Mac        &kp _UNDO_Mac
                                          &tog LAYER_System   &tog LAYER_Cursor  &tog LAYER_Mouse  &tog LAYER_Symbol    &tog LAYER_Number  &tog LAYER_Function
            >;
        };

        layer_Button {
            bindings = <
              &none           &kp PSCRN             &kp ESC             &kp RET       &select_all        &select_all              &kp RET              &kp ESC            &kp PSCRN                &none
 &kp LEFT_PINKY_MOD  &kp LEFT_RINGY_MOD  &kp LEFT_MIDDY_MOD  &kp LEFT_INDEX_MOD         &kp _UNDO          &kp _UNDO  &kp RIGHT_INDEX_MOD  &kp RIGHT_MIDDY_MOD  &kp RIGHT_RINGY_MOD  &kp RIGHT_PINKY_MOD
          &kp _UNDO            &kp _CUT           &kp _COPY          &kp _PASTE         &kp _REDO          &kp _REDO           &kp _PASTE            &kp _COPY             &kp _CUT            &kp _UNDO
                                          &tog LAYER_System   &tog LAYER_Cursor  &tog LAYER_Mouse  &tog LAYER_Symbol    &tog LAYER_Number  &tog LAYER_Function
            >;
        };
    };
};
